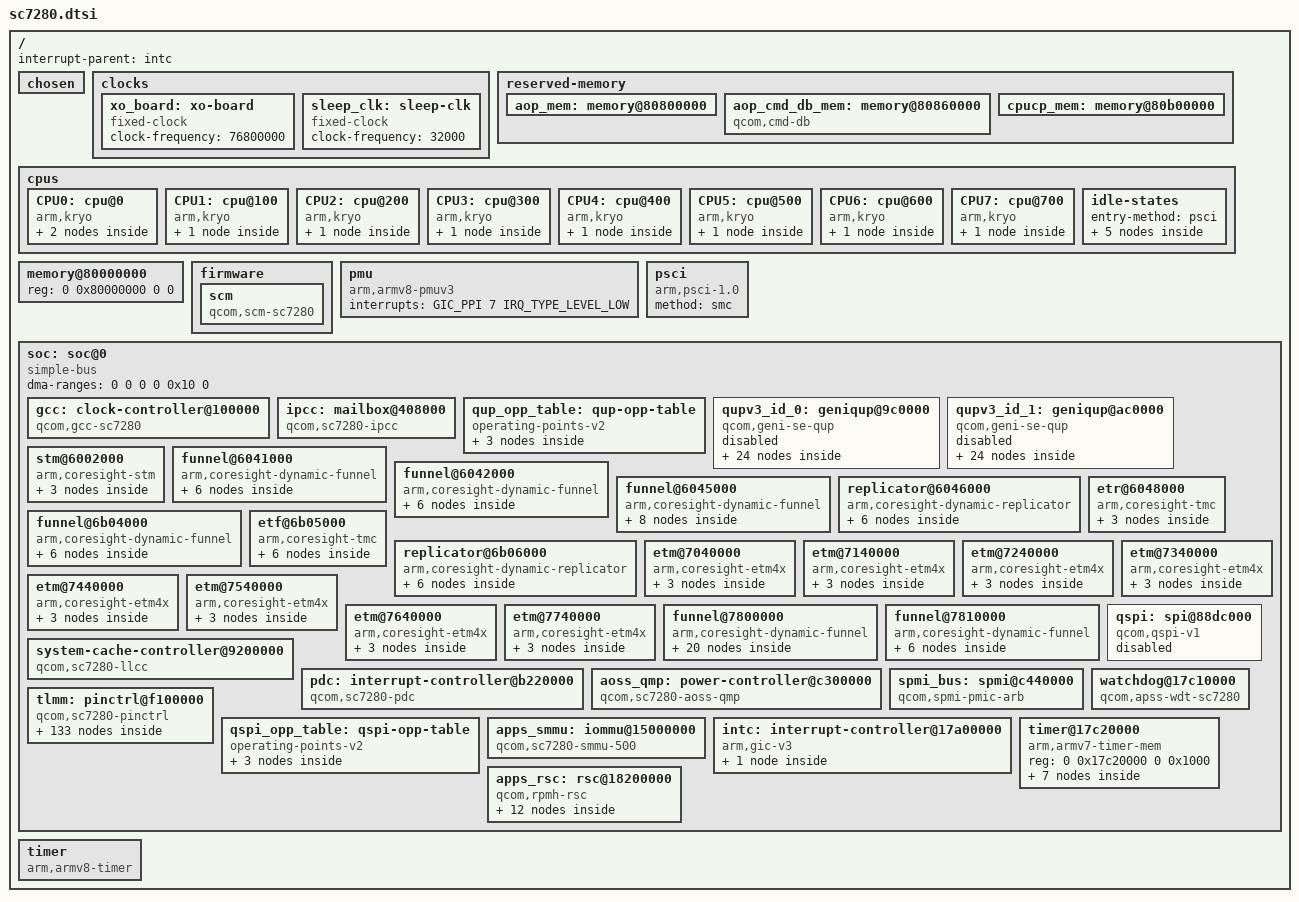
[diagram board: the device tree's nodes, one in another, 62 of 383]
// SPDX-License-Identifier: BSD-3-Clause
/*
 * sc7280 SoC device tree source
 *
 * Copyright (c) 2020-2021, The Linux Foundation. All rights reserved.
 */

#include <dt-bindings/clock/qcom,gcc-sc7280.h>
#include <dt-bindings/clock/qcom,rpmh.h>
#include <dt-bindings/interrupt-controller/arm-gic.h>
#include <dt-bindings/mailbox/qcom-ipcc.h>
#include <dt-bindings/power/qcom-aoss-qmp.h>
#include <dt-bindings/power/qcom-rpmpd.h>
#include <dt-bindings/soc/qcom,rpmh-rsc.h>

/ {
	interrupt-parent = <&intc>;

	#address-cells = <2>;
	#size-cells = <2>;

	chosen { };

	clocks {
		xo_board: xo-board {
			compatible = "fixed-clock";
			clock-frequency = <76800000>;
			#clock-cells = <0>;
		};

		sleep_clk: sleep-clk {
			compatible = "fixed-clock";
			clock-frequency = <32000>;
			#clock-cells = <0>;
		};
	};

	reserved-memory {
		#address-cells = <2>;
		#size-cells = <2>;
		ranges;

		aop_mem: memory@80800000 {
			reg = <0x0 0x80800000 0x0 0x60000>;
			no-map;
		};

		aop_cmd_db_mem: memory@80860000 {
			reg = <0x0 0x80860000 0x0 0x20000>;
			compatible = "qcom,cmd-db";
			no-map;
		};

		cpucp_mem: memory@80b00000 {
			no-map;
			reg = <0x0 0x80b00000 0x0 0x100000>;
		};
	};

	cpus {
		#address-cells = <2>;
		#size-cells = <0>;

		CPU0: cpu@0 {
			device_type = "cpu";
			compatible = "arm,kryo";
			reg = <0x0 0x0>;
			enable-method = "psci";
			cpu-idle-states = <&LITTLE_CPU_SLEEP_0
					   &LITTLE_CPU_SLEEP_1
					   &CLUSTER_SLEEP_0>;
			next-level-cache = <&L2_0>;
			L2_0: l2-cache {
				compatible = "cache";
				next-level-cache = <&L3_0>;
				L3_0: l3-cache {
					compatible = "cache";
				};
			};
		};

		CPU1: cpu@100 {
			device_type = "cpu";
			compatible = "arm,kryo";
			reg = <0x0 0x100>;
			enable-method = "psci";
			cpu-idle-states = <&LITTLE_CPU_SLEEP_0
					   &LITTLE_CPU_SLEEP_1
					   &CLUSTER_SLEEP_0>;
			next-level-cache = <&L2_100>;
			L2_100: l2-cache {
				compatible = "cache";
				next-level-cache = <&L3_0>;
			};
		};

		CPU2: cpu@200 {
			device_type = "cpu";
			compatible = "arm,kryo";
			reg = <0x0 0x200>;
			enable-method = "psci";
			cpu-idle-states = <&LITTLE_CPU_SLEEP_0
					   &LITTLE_CPU_SLEEP_1
					   &CLUSTER_SLEEP_0>;
			next-level-cache = <&L2_200>;
			L2_200: l2-cache {
				compatible = "cache";
				next-level-cache = <&L3_0>;
			};
		};

		CPU3: cpu@300 {
			device_type = "cpu";
			compatible = "arm,kryo";
			reg = <0x0 0x300>;
			enable-method = "psci";
			cpu-idle-states = <&LITTLE_CPU_SLEEP_0
					   &LITTLE_CPU_SLEEP_1
					   &CLUSTER_SLEEP_0>;
			next-level-cache = <&L2_300>;
			L2_300: l2-cache {
				compatible = "cache";
				next-level-cache = <&L3_0>;
			};
		};

		CPU4: cpu@400 {
			device_type = "cpu";
			compatible = "arm,kryo";
			reg = <0x0 0x400>;
			enable-method = "psci";
			cpu-idle-states = <&BIG_CPU_SLEEP_0
					   &BIG_CPU_SLEEP_1
					   &CLUSTER_SLEEP_0>;
			next-level-cache = <&L2_400>;
			L2_400: l2-cache {
				compatible = "cache";
				next-level-cache = <&L3_0>;
			};
		};

		CPU5: cpu@500 {
			device_type = "cpu";
			compatible = "arm,kryo";
			reg = <0x0 0x500>;
			enable-method = "psci";
			cpu-idle-states = <&BIG_CPU_SLEEP_0
					   &BIG_CPU_SLEEP_1
					   &CLUSTER_SLEEP_0>;
			next-level-cache = <&L2_500>;
			L2_500: l2-cache {
				compatible = "cache";
				next-level-cache = <&L3_0>;
			};
		};

		CPU6: cpu@600 {
			device_type = "cpu";
			compatible = "arm,kryo";
			reg = <0x0 0x600>;
			enable-method = "psci";
			cpu-idle-states = <&BIG_CPU_SLEEP_0
					   &BIG_CPU_SLEEP_1
					   &CLUSTER_SLEEP_0>;
			next-level-cache = <&L2_600>;
			L2_600: l2-cache {
				compatible = "cache";
				next-level-cache = <&L3_0>;
			};
		};

		CPU7: cpu@700 {
			device_type = "cpu";
			compatible = "arm,kryo";
			reg = <0x0 0x700>;
			enable-method = "psci";
			cpu-idle-states = <&BIG_CPU_SLEEP_0
					   &BIG_CPU_SLEEP_1
					   &CLUSTER_SLEEP_0>;
			next-level-cache = <&L2_700>;
			L2_700: l2-cache {
				compatible = "cache";
				next-level-cache = <&L3_0>;
			};
		};

		idle-states {
			entry-method = "psci";

			LITTLE_CPU_SLEEP_0: cpu-sleep-0-0 {
				compatible = "arm,idle-state";
				idle-state-name = "little-power-down";
				arm,psci-suspend-param = <0x40000003>;
				entry-latency-us = <549>;
				exit-latency-us = <901>;
				min-residency-us = <1774>;
				local-timer-stop;
			};

			LITTLE_CPU_SLEEP_1: cpu-sleep-0-1 {
				compatible = "arm,idle-state";
				idle-state-name = "little-rail-power-down";
				arm,psci-suspend-param = <0x40000004>;
				entry-latency-us = <702>;
				exit-latency-us = <915>;
				min-residency-us = <4001>;
				local-timer-stop;
			};

			BIG_CPU_SLEEP_0: cpu-sleep-1-0 {
				compatible = "arm,idle-state";
				idle-state-name = "big-power-down";
				arm,psci-suspend-param = <0x40000003>;
				entry-latency-us = <523>;
				exit-latency-us = <1244>;
				min-residency-us = <2207>;
				local-timer-stop;
			};

			BIG_CPU_SLEEP_1: cpu-sleep-1-1 {
				compatible = "arm,idle-state";
				idle-state-name = "big-rail-power-down";
				arm,psci-suspend-param = <0x40000004>;
				entry-latency-us = <526>;
				exit-latency-us = <1854>;
				min-residency-us = <5555>;
				local-timer-stop;
			};

			CLUSTER_SLEEP_0: cluster-sleep-0 {
				compatible = "arm,idle-state";
				idle-state-name = "cluster-power-down";
				arm,psci-suspend-param = <0x40003444>;
				entry-latency-us = <3263>;
				exit-latency-us = <6562>;
				min-residency-us = <9926>;
				local-timer-stop;
			};
		};
	};

	memory@80000000 {
		device_type = "memory";
		/* We expect the bootloader to fill in the size */
		reg = <0 0x80000000 0 0>;
	};

	firmware {
		scm {
			compatible = "qcom,scm-sc7280", "qcom,scm";
		};
	};

	pmu {
		compatible = "arm,armv8-pmuv3";
		interrupts = <GIC_PPI 7 IRQ_TYPE_LEVEL_LOW>;
	};

	psci {
		compatible = "arm,psci-1.0";
		method = "smc";
	};

	soc: soc@0 {
		#address-cells = <2>;
		#size-cells = <2>;
		ranges = <0 0 0 0 0x10 0>;
		dma-ranges = <0 0 0 0 0x10 0>;
		compatible = "simple-bus";

		gcc: clock-controller@100000 {
			compatible = "qcom,gcc-sc7280";
			reg = <0 0x00100000 0 0x1f0000>;
			clocks = <&rpmhcc RPMH_CXO_CLK>,
				 <&rpmhcc RPMH_CXO_CLK_A>, <&sleep_clk>,
				 <0>, <0>, <0>, <0>, <0>, <0>;
			clock-names = "bi_tcxo", "bi_tcxo_ao", "sleep_clk",
				      "pcie_0_pipe_clk", "pcie_1_pipe-clk",
				      "ufs_phy_rx_symbol_0_clk", "ufs_phy_rx_symbol_1_clk",
				      "ufs_phy_tx_symbol_0_clk",
				      "usb3_phy_wrapper_gcc_usb30_pipe_clk";
			#clock-cells = <1>;
			#reset-cells = <1>;
			#power-domain-cells = <1>;
		};

		ipcc: mailbox@408000 {
			compatible = "qcom,sc7280-ipcc", "qcom,ipcc";
			reg = <0 0x00408000 0 0x1000>;
			interrupts = <GIC_SPI 229 IRQ_TYPE_LEVEL_HIGH>;
			interrupt-controller;
			#interrupt-cells = <3>;
			#mbox-cells = <2>;
		};

		qup_opp_table: qup-opp-table {
			compatible = "operating-points-v2";

			opp-75000000 {
				opp-hz = /bits/ 64 <75000000>;
				required-opps = <&rpmhpd_opp_low_svs>;
			};

			opp-100000000 {
				opp-hz = /bits/ 64 <100000000>;
				required-opps = <&rpmhpd_opp_svs>;
			};

			opp-128000000 {
				opp-hz = /bits/ 64 <128000000>;
				required-opps = <&rpmhpd_opp_nom>;
			};
		};

		qupv3_id_0: geniqup@9c0000 {
			compatible = "qcom,geni-se-qup";
			reg = <0 0x009c0000 0 0x2000>;
			clock-names = "m-ahb", "s-ahb";
			clocks = <&gcc GCC_QUPV3_WRAP_0_M_AHB_CLK>,
				 <&gcc GCC_QUPV3_WRAP_0_S_AHB_CLK>;
			#address-cells = <2>;
			#size-cells = <2>;
			ranges;
			iommus = <&apps_smmu 0x123 0x0>;
			interconnects = <&clk_virt MASTER_QUP_CORE_0 0 &clk_virt SLAVE_QUP_CORE_0 0>;
			interconnect-names = "qup-core";
			status = "disabled";

			i2c0: i2c@980000 {
				compatible = "qcom,geni-i2c";
				reg = <0 0x00980000 0 0x4000>;
				clock-names = "se";
				clocks = <&gcc GCC_QUPV3_WRAP0_S0_CLK>;
				pinctrl-names = "default";
				pinctrl-0 = <&qup_i2c0_data_clk>;
				interrupts = <GIC_SPI 601 IRQ_TYPE_LEVEL_HIGH>;
				#address-cells = <1>;
				#size-cells = <0>;
				interconnects = <&clk_virt MASTER_QUP_CORE_0 0 &clk_virt SLAVE_QUP_CORE_0 0>,
						<&gem_noc MASTER_APPSS_PROC 0 &cnoc2 SLAVE_QUP_0 0>,
						<&aggre1_noc MASTER_QUP_0 0 &mc_virt SLAVE_EBI1 0>;
				interconnect-names = "qup-core", "qup-config",
							"qup-memory";
				status = "disabled";
			};

			spi0: spi@980000 {
				compatible = "qcom,geni-spi";
				reg = <0 0x00980000 0 0x4000>;
				clock-names = "se";
				clocks = <&gcc GCC_QUPV3_WRAP0_S0_CLK>;
				pinctrl-names = "default";
				pinctrl-0 = <&qup_spi0_data_clk>, <&qup_spi0_cs>, <&qup_spi0_cs_gpio>;
				interrupts = <GIC_SPI 601 IRQ_TYPE_LEVEL_HIGH>;
				#address-cells = <1>;
				#size-cells = <0>;
				power-domains = <&rpmhpd SC7280_CX>;
				operating-points-v2 = <&qup_opp_table>;
				interconnects = <&clk_virt MASTER_QUP_CORE_0 0 &clk_virt SLAVE_QUP_CORE_0 0>,
						<&gem_noc MASTER_APPSS_PROC 0 &cnoc2 SLAVE_QUP_0 0>;
				interconnect-names = "qup-core", "qup-config";
				status = "disabled";
			};

			uart0: serial@980000 {
				compatible = "qcom,geni-uart";
				reg = <0 0x00980000 0 0x4000>;
				clock-names = "se";
				clocks = <&gcc GCC_QUPV3_WRAP0_S0_CLK>;
				pinctrl-names = "default";
				pinctrl-0 = <&qup_uart0_cts>, <&qup_uart0_rts>, <&qup_uart0_tx>, <&qup_uart0_rx>;
				interrupts = <GIC_SPI 601 IRQ_TYPE_LEVEL_HIGH>;
				power-domains = <&rpmhpd SC7280_CX>;
				operating-points-v2 = <&qup_opp_table>;
				interconnects = <&clk_virt MASTER_QUP_CORE_0 0 &clk_virt SLAVE_QUP_CORE_0 0>,
						<&gem_noc MASTER_APPSS_PROC 0 &cnoc2 SLAVE_QUP_0 0>;
				interconnect-names = "qup-core", "qup-config";
				status = "disabled";
			};

			i2c1: i2c@984000 {
				compatible = "qcom,geni-i2c";
				reg = <0 0x00984000 0 0x4000>;
				clock-names = "se";
				clocks = <&gcc GCC_QUPV3_WRAP0_S1_CLK>;
				pinctrl-names = "default";
				pinctrl-0 = <&qup_i2c1_data_clk>;
				interrupts = <GIC_SPI 602 IRQ_TYPE_LEVEL_HIGH>;
				#address-cells = <1>;
				#size-cells = <0>;
				interconnects = <&clk_virt MASTER_QUP_CORE_0 0 &clk_virt SLAVE_QUP_CORE_0 0>,
						<&gem_noc MASTER_APPSS_PROC 0 &cnoc2 SLAVE_QUP_0 0>,
						<&aggre1_noc MASTER_QUP_0 0 &mc_virt SLAVE_EBI1 0>;
				interconnect-names = "qup-core", "qup-config",
							"qup-memory";
				status = "disabled";
			};

			spi1: spi@984000 {
				compatible = "qcom,geni-spi";
				reg = <0 0x00984000 0 0x4000>;
				clock-names = "se";
				clocks = <&gcc GCC_QUPV3_WRAP0_S1_CLK>;
				pinctrl-names = "default";
				pinctrl-0 = <&qup_spi1_data_clk>, <&qup_spi1_cs>, <&qup_spi1_cs_gpio>;
				interrupts = <GIC_SPI 602 IRQ_TYPE_LEVEL_HIGH>;
				#address-cells = <1>;
				#size-cells = <0>;
				power-domains = <&rpmhpd SC7280_CX>;
				operating-points-v2 = <&qup_opp_table>;
				interconnects = <&clk_virt MASTER_QUP_CORE_0 0 &clk_virt SLAVE_QUP_CORE_0 0>,
						<&gem_noc MASTER_APPSS_PROC 0 &cnoc2 SLAVE_QUP_0 0>;
				interconnect-names = "qup-core", "qup-config";
				status = "disabled";
			};

			uart1: serial@984000 {
				compatible = "qcom,geni-uart";
				reg = <0 0x00984000 0 0x4000>;
				clock-names = "se";
				clocks = <&gcc GCC_QUPV3_WRAP0_S1_CLK>;
				pinctrl-names = "default";
				pinctrl-0 = <&qup_uart1_cts>, <&qup_uart1_rts>, <&qup_uart1_tx>, <&qup_uart1_rx>;
				interrupts = <GIC_SPI 602 IRQ_TYPE_LEVEL_HIGH>;
				power-domains = <&rpmhpd SC7280_CX>;
				operating-points-v2 = <&qup_opp_table>;
				interconnects = <&clk_virt MASTER_QUP_CORE_0 0 &clk_virt SLAVE_QUP_CORE_0 0>,
						<&gem_noc MASTER_APPSS_PROC 0 &cnoc2 SLAVE_QUP_0 0>;
				interconnect-names = "qup-core", "qup-config";
				status = "disabled";
			};

			i2c2: i2c@988000 {
				compatible = "qcom,geni-i2c";
				reg = <0 0x00988000 0 0x4000>;
				clock-names = "se";
				clocks = <&gcc GCC_QUPV3_WRAP0_S2_CLK>;
				pinctrl-names = "default";
				pinctrl-0 = <&qup_i2c2_data_clk>;
				interrupts = <GIC_SPI 603 IRQ_TYPE_LEVEL_HIGH>;
				#address-cells = <1>;
				#size-cells = <0>;
				interconnects = <&clk_virt MASTER_QUP_CORE_0 0 &clk_virt SLAVE_QUP_CORE_0 0>,
						<&gem_noc MASTER_APPSS_PROC 0 &cnoc2 SLAVE_QUP_0 0>,
						<&aggre1_noc MASTER_QUP_0 0 &mc_virt SLAVE_EBI1 0>;
				interconnect-names = "qup-core", "qup-config",
							"qup-memory";
				status = "disabled";
			};

			spi2: spi@988000 {
				compatible = "qcom,geni-spi";
				reg = <0 0x00988000 0 0x4000>;
				clock-names = "se";
				clocks = <&gcc GCC_QUPV3_WRAP0_S2_CLK>;
				pinctrl-names = "default";
				pinctrl-0 = <&qup_spi2_data_clk>, <&qup_spi2_cs>, <&qup_spi2_cs_gpio>;
				interrupts = <GIC_SPI 603 IRQ_TYPE_LEVEL_HIGH>;
				#address-cells = <1>;
				#size-cells = <0>;
				power-domains = <&rpmhpd SC7280_CX>;
				operating-points-v2 = <&qup_opp_table>;
				interconnects = <&clk_virt MASTER_QUP_CORE_0 0 &clk_virt SLAVE_QUP_CORE_0 0>,
						<&gem_noc MASTER_APPSS_PROC 0 &cnoc2 SLAVE_QUP_0 0>;
				interconnect-names = "qup-core", "qup-config";
				status = "disabled";
			};

			uart2: serial@988000 {
				compatible = "qcom,geni-uart";
				reg = <0 0x00988000 0 0x4000>;
				clock-names = "se";
				clocks = <&gcc GCC_QUPV3_WRAP0_S2_CLK>;
				pinctrl-names = "default";
				pinctrl-0 = <&qup_uart2_cts>, <&qup_uart2_rts>, <&qup_uart2_tx>, <&qup_uart2_rx>;
				interrupts = <GIC_SPI 603 IRQ_TYPE_LEVEL_HIGH>;
				power-domains = <&rpmhpd SC7280_CX>;
				operating-points-v2 = <&qup_opp_table>;
				interconnects = <&clk_virt MASTER_QUP_CORE_0 0 &clk_virt SLAVE_QUP_CORE_0 0>,
						<&gem_noc MASTER_APPSS_PROC 0 &cnoc2 SLAVE_QUP_0 0>;
				interconnect-names = "qup-core", "qup-config";
				status = "disabled";
			};

			i2c3: i2c@98c000 {
				compatible = "qcom,geni-i2c";
				reg = <0 0x0098c000 0 0x4000>;
				clock-names = "se";
				clocks = <&gcc GCC_QUPV3_WRAP0_S3_CLK>;
				pinctrl-names = "default";
				pinctrl-0 = <&qup_i2c3_data_clk>;
				interrupts = <GIC_SPI 604 IRQ_TYPE_LEVEL_HIGH>;
				#address-cells = <1>;
				#size-cells = <0>;
				interconnects = <&clk_virt MASTER_QUP_CORE_0 0 &clk_virt SLAVE_QUP_CORE_0 0>,
						<&gem_noc MASTER_APPSS_PROC 0 &cnoc2 SLAVE_QUP_0 0>,
						<&aggre1_noc MASTER_QUP_0 0 &mc_virt SLAVE_EBI1 0>;
				interconnect-names = "qup-core", "qup-config",
							"qup-memory";
				status = "disabled";
			};

			spi3: spi@98c000 {
				compatible = "qcom,geni-spi";
				reg = <0 0x0098c000 0 0x4000>;
				clock-names = "se";
				clocks = <&gcc GCC_QUPV3_WRAP0_S3_CLK>;
				pinctrl-names = "default";
				pinctrl-0 = <&qup_spi3_data_clk>, <&qup_spi3_cs>, <&qup_spi3_cs_gpio>;
				interrupts = <GIC_SPI 604 IRQ_TYPE_LEVEL_HIGH>;
				#address-cells = <1>;
				#size-cells = <0>;
				power-domains = <&rpmhpd SC7280_CX>;
				operating-points-v2 = <&qup_opp_table>;
				interconnects = <&clk_virt MASTER_QUP_CORE_0 0 &clk_virt SLAVE_QUP_CORE_0 0>,
						<&gem_noc MASTER_APPSS_PROC 0 &cnoc2 SLAVE_QUP_0 0>;
				interconnect-names = "qup-core", "qup-config";
				status = "disabled";
			};

			uart3: serial@98c000 {
				compatible = "qcom,geni-uart";
				reg = <0 0x0098c000 0 0x4000>;
				clock-names = "se";
				clocks = <&gcc GCC_QUPV3_WRAP0_S3_CLK>;
				pinctrl-names = "default";
				pinctrl-0 = <&qup_uart3_cts>, <&qup_uart3_rts>, <&qup_uart3_tx>, <&qup_uart3_rx>;
				interrupts = <GIC_SPI 604 IRQ_TYPE_LEVEL_HIGH>;
				power-domains = <&rpmhpd SC7280_CX>;
				operating-points-v2 = <&qup_opp_table>;
				interconnects = <&clk_virt MASTER_QUP_CORE_0 0 &clk_virt SLAVE_QUP_CORE_0 0>,
						<&gem_noc MASTER_APPSS_PROC 0 &cnoc2 SLAVE_QUP_0 0>;
				interconnect-names = "qup-core", "qup-config";
				status = "disabled";
			};

			i2c4: i2c@990000 {
				compatible = "qcom,geni-i2c";
				reg = <0 0x00990000 0 0x4000>;
				clock-names = "se";
				clocks = <&gcc GCC_QUPV3_WRAP0_S4_CLK>;
				pinctrl-names = "default";
				pinctrl-0 = <&qup_i2c4_data_clk>;
				interrupts = <GIC_SPI 605 IRQ_TYPE_LEVEL_HIGH>;
				#address-cells = <1>;
				#size-cells = <0>;
				interconnects = <&clk_virt MASTER_QUP_CORE_0 0 &clk_virt SLAVE_QUP_CORE_0 0>,
						<&gem_noc MASTER_APPSS_PROC 0 &cnoc2 SLAVE_QUP_0 0>,
						<&aggre1_noc MASTER_QUP_0 0 &mc_virt SLAVE_EBI1 0>;
				interconnect-names = "qup-core", "qup-config",
							"qup-memory";
				status = "disabled";
			};

			spi4: spi@990000 {
				compatible = "qcom,geni-spi";
				reg = <0 0x00990000 0 0x4000>;
				clock-names = "se";
				clocks = <&gcc GCC_QUPV3_WRAP0_S4_CLK>;
				pinctrl-names = "default";
				pinctrl-0 = <&qup_spi4_data_clk>, <&qup_spi4_cs>, <&qup_spi4_cs_gpio>;
				interrupts = <GIC_SPI 605 IRQ_TYPE_LEVEL_HIGH>;
				#address-cells = <1>;
				#size-cells = <0>;
				power-domains = <&rpmhpd SC7280_CX>;
				operating-points-v2 = <&qup_opp_table>;
				interconnects = <&clk_virt MASTER_QUP_CORE_0 0 &clk_virt SLAVE_QUP_CORE_0 0>,
						<&gem_noc MASTER_APPSS_PROC 0 &cnoc2 SLAVE_QUP_0 0>;
				interconnect-names = "qup-core", "qup-config";
				status = "disabled";
			};

			uart4: serial@990000 {
				compatible = "qcom,geni-uart";
				reg = <0 0x00990000 0 0x4000>;
				clock-names = "se";
				clocks = <&gcc GCC_QUPV3_WRAP0_S4_CLK>;
				pinctrl-names = "default";
				pinctrl-0 = <&qup_uart4_cts>, <&qup_uart4_rts>, <&qup_uart4_tx>, <&qup_uart4_rx>;
				interrupts = <GIC_SPI 605 IRQ_TYPE_LEVEL_HIGH>;
				power-domains = <&rpmhpd SC7280_CX>;
				operating-points-v2 = <&qup_opp_table>;
				interconnects = <&clk_virt MASTER_QUP_CORE_0 0 &clk_virt SLAVE_QUP_CORE_0 0>,
						<&gem_noc MASTER_APPSS_PROC 0 &cnoc2 SLAVE_QUP_0 0>;
				interconnect-names = "qup-core", "qup-config";
				status = "disabled";
			};

			i2c5: i2c@994000 {
				compatible = "qcom,geni-i2c";
				reg = <0 0x00994000 0 0x4000>;
				clock-names = "se";
				clocks = <&gcc GCC_QUPV3_WRAP0_S5_CLK>;
				pinctrl-names = "default";
				pinctrl-0 = <&qup_i2c5_data_clk>;
				interrupts = <GIC_SPI 606 IRQ_TYPE_LEVEL_HIGH>;
				#address-cells = <1>;
				#size-cells = <0>;
				interconnects = <&clk_virt MASTER_QUP_CORE_0 0 &clk_virt SLAVE_QUP_CORE_0 0>,
						<&gem_noc MASTER_APPSS_PROC 0 &cnoc2 SLAVE_QUP_0 0>,
						<&aggre1_noc MASTER_QUP_0 0 &mc_virt SLAVE_EBI1 0>;
				interconnect-names = "qup-core", "qup-config",
							"qup-memory";
				status = "disabled";
			};

			spi5: spi@994000 {
				compatible = "qcom,geni-spi";
				reg = <0 0x00994000 0 0x4000>;
				clock-names = "se";
				clocks = <&gcc GCC_QUPV3_WRAP0_S5_CLK>;
				pinctrl-names = "default";
				pinctrl-0 = <&qup_spi5_data_clk>, <&qup_spi5_cs>, <&qup_spi5_cs_gpio>;
				interrupts = <GIC_SPI 606 IRQ_TYPE_LEVEL_HIGH>;
				#address-cells = <1>;
				#size-cells = <0>;
				power-domains = <&rpmhpd SC7280_CX>;
				operating-points-v2 = <&qup_opp_table>;
				interconnects = <&clk_virt MASTER_QUP_CORE_0 0 &clk_virt SLAVE_QUP_CORE_0 0>,
						<&gem_noc MASTER_APPSS_PROC 0 &cnoc2 SLAVE_QUP_0 0>;
				interconnect-names = "qup-core", "qup-config";
				status = "disabled";
			};

			uart5: serial@994000 {
				compatible = "qcom,geni-debug-uart";
				reg = <0 0x00994000 0 0x4000>;
				clock-names = "se";
				clocks = <&gcc GCC_QUPV3_WRAP0_S5_CLK>;
				pinctrl-names = "default";
				pinctrl-0 = <&qup_uart5_cts>, <&qup_uart5_rts>, <&qup_uart5_tx>, <&qup_uart5_rx>;
				interrupts = <GIC_SPI 606 IRQ_TYPE_LEVEL_HIGH>;
				power-domains = <&rpmhpd SC7280_CX>;
				operating-points-v2 = <&qup_opp_table>;
				interconnects = <&clk_virt MASTER_QUP_CORE_0 0 &clk_virt SLAVE_QUP_CORE_0 0>,
						<&gem_noc MASTER_APPSS_PROC 0 &cnoc2 SLAVE_QUP_0 0>;
				interconnect-names = "qup-core", "qup-config";
				status = "disabled";
			};

			i2c6: i2c@998000 {
				compatible = "qcom,geni-i2c";
				reg = <0 0x00998000 0 0x4000>;
				clock-names = "se";
				clocks = <&gcc GCC_QUPV3_WRAP0_S6_CLK>;
				pinctrl-names = "default";
				pinctrl-0 = <&qup_i2c6_data_clk>;
				interrupts = <GIC_SPI 607 IRQ_TYPE_LEVEL_HIGH>;
				#address-cells = <1>;
				#size-cells = <0>;
				interconnects = <&clk_virt MASTER_QUP_CORE_0 0 &clk_virt SLAVE_QUP_CORE_0 0>,
						<&gem_noc MASTER_APPSS_PROC 0 &cnoc2 SLAVE_QUP_0 0>,
						<&aggre1_noc MASTER_QUP_0 0 &mc_virt SLAVE_EBI1 0>;
				interconnect-names = "qup-core", "qup-config",
							"qup-memory";
				status = "disabled";
			};

			spi6: spi@998000 {
				compatible = "qcom,geni-spi";
				reg = <0 0x00998000 0 0x4000>;
				clock-names = "se";
				clocks = <&gcc GCC_QUPV3_WRAP0_S6_CLK>;
				pinctrl-names = "default";
				pinctrl-0 = <&qup_spi6_data_clk>, <&qup_spi6_cs>, <&qup_spi6_cs_gpio>;
				interrupts = <GIC_SPI 607 IRQ_TYPE_LEVEL_HIGH>;
				#address-cells = <1>;
				#size-cells = <0>;
				power-domains = <&rpmhpd SC7280_CX>;
				operating-points-v2 = <&qup_opp_table>;
				interconnects = <&clk_virt MASTER_QUP_CORE_0 0 &clk_virt SLAVE_QUP_CORE_0 0>,
						<&gem_noc MASTER_APPSS_PROC 0 &cnoc2 SLAVE_QUP_0 0>;
				interconnect-names = "qup-core", "qup-config";
				status = "disabled";
			};

			uart6: serial@998000 {
				compatible = "qcom,geni-uart";
				reg = <0 0x00998000 0 0x4000>;
				clock-names = "se";
				clocks = <&gcc GCC_QUPV3_WRAP0_S6_CLK>;
				pinctrl-names = "default";
				pinctrl-0 = <&qup_uart6_cts>, <&qup_uart6_rts>, <&qup_uart6_tx>, <&qup_uart6_rx>;
				interrupts = <GIC_SPI 607 IRQ_TYPE_LEVEL_HIGH>;
				power-domains = <&rpmhpd SC7280_CX>;
				operating-points-v2 = <&qup_opp_table>;
				interconnects = <&clk_virt MASTER_QUP_CORE_0 0 &clk_virt SLAVE_QUP_CORE_0 0>,
						<&gem_noc MASTER_APPSS_PROC 0 &cnoc2 SLAVE_QUP_0 0>;
				interconnect-names = "qup-core", "qup-config";
				status = "disabled";
			};

			i2c7: i2c@99c000 {
				compatible = "qcom,geni-i2c";
				reg = <0 0x0099c000 0 0x4000>;
				clock-names = "se";
				clocks = <&gcc GCC_QUPV3_WRAP0_S7_CLK>;
				pinctrl-names = "default";
				pinctrl-0 = <&qup_i2c7_data_clk>;
				interrupts = <GIC_SPI 608 IRQ_TYPE_LEVEL_HIGH>;
				#address-cells = <1>;
				#size-cells = <0>;
				interconnects = <&clk_virt MASTER_QUP_CORE_0 0 &clk_virt SLAVE_QUP_CORE_0 0>,
						<&gem_noc MASTER_APPSS_PROC 0 &cnoc2 SLAVE_QUP_0 0>,
						<&aggre1_noc MASTER_QUP_0 0 &mc_virt SLAVE_EBI1 0>;
				interconnect-names = "qup-core", "qup-config",
							"qup-memory";
				status = "disabled";
			};

			spi7: spi@99c000 {
				compatible = "qcom,geni-spi";
				reg = <0 0x0099c000 0 0x4000>;
				clock-names = "se";
				clocks = <&gcc GCC_QUPV3_WRAP0_S7_CLK>;
				pinctrl-names = "default";
				pinctrl-0 = <&qup_spi7_data_clk>, <&qup_spi7_cs>, <&qup_spi7_cs_gpio>;
				interrupts = <GIC_SPI 608 IRQ_TYPE_LEVEL_HIGH>;
				#address-cells = <1>;
				#size-cells = <0>;
				power-domains = <&rpmhpd SC7280_CX>;
				operating-points-v2 = <&qup_opp_table>;
				interconnects = <&clk_virt MASTER_QUP_CORE_0 0 &clk_virt SLAVE_QUP_CORE_0 0>,
						<&gem_noc MASTER_APPSS_PROC 0 &cnoc2 SLAVE_QUP_0 0>;
				interconnect-names = "qup-core", "qup-config";
				status = "disabled";
			};

			uart7: serial@99c000 {
				compatible = "qcom,geni-uart";
				reg = <0 0x0099c000 0 0x4000>;
				clock-names = "se";
				clocks = <&gcc GCC_QUPV3_WRAP0_S7_CLK>;
				pinctrl-names = "default";
				pinctrl-0 = <&qup_uart7_cts>, <&qup_uart7_rts>, <&qup_uart7_tx>, <&qup_uart7_rx>;
				interrupts = <GIC_SPI 608 IRQ_TYPE_LEVEL_HIGH>;
				power-domains = <&rpmhpd SC7280_CX>;
				operating-points-v2 = <&qup_opp_table>;
				interconnects = <&clk_virt MASTER_QUP_CORE_0 0 &clk_virt SLAVE_QUP_CORE_0 0>,
						<&gem_noc MASTER_APPSS_PROC 0 &cnoc2 SLAVE_QUP_0 0>;
				interconnect-names = "qup-core", "qup-config";
				status = "disabled";
			};
		};

		qupv3_id_1: geniqup@ac0000 {
			compatible = "qcom,geni-se-qup";
			reg = <0 0x00ac0000 0 0x2000>;
			clock-names = "m-ahb", "s-ahb";
			clocks = <&gcc GCC_QUPV3_WRAP_1_M_AHB_CLK>,
				 <&gcc GCC_QUPV3_WRAP_1_S_AHB_CLK>;
			#address-cells = <2>;
			#size-cells = <2>;
			ranges;
			iommus = <&apps_smmu 0x43 0x0>;
			interconnects = <&clk_virt MASTER_QUP_CORE_1 0 &clk_virt SLAVE_QUP_CORE_1 0>;
			interconnect-names = "qup-core";
			status = "disabled";

			i2c8: i2c@a80000 {
				compatible = "qcom,geni-i2c";
				reg = <0 0x00a80000 0 0x4000>;
				clock-names = "se";
				clocks = <&gcc GCC_QUPV3_WRAP1_S0_CLK>;
				pinctrl-names = "default";
				pinctrl-0 = <&qup_i2c8_data_clk>;
				interrupts = <GIC_SPI 353 IRQ_TYPE_LEVEL_HIGH>;
				#address-cells = <1>;
				#size-cells = <0>;
				interconnects = <&clk_virt MASTER_QUP_CORE_1 0 &clk_virt SLAVE_QUP_CORE_1 0>,
						<&gem_noc MASTER_APPSS_PROC 0 &cnoc2 SLAVE_QUP_1 0>,
						<&aggre2_noc MASTER_QUP_1 0 &mc_virt SLAVE_EBI1 0>;
				interconnect-names = "qup-core", "qup-config",
							"qup-memory";
				status = "disabled";
			};

			spi8: spi@a80000 {
				compatible = "qcom,geni-spi";
				reg = <0 0x00a80000 0 0x4000>;
				clock-names = "se";
				clocks = <&gcc GCC_QUPV3_WRAP1_S0_CLK>;
				pinctrl-names = "default";
				pinctrl-0 = <&qup_spi8_data_clk>, <&qup_spi8_cs>, <&qup_spi8_cs_gpio>;
				interrupts = <GIC_SPI 353 IRQ_TYPE_LEVEL_HIGH>;
				#address-cells = <1>;
				#size-cells = <0>;
				power-domains = <&rpmhpd SC7280_CX>;
				operating-points-v2 = <&qup_opp_table>;
				interconnects = <&clk_virt MASTER_QUP_CORE_1 0 &clk_virt SLAVE_QUP_CORE_1 0>,
						<&gem_noc MASTER_APPSS_PROC 0 &cnoc2 SLAVE_QUP_1 0>;
				interconnect-names = "qup-core", "qup-config";
				status = "disabled";
			};

			uart8: serial@a80000 {
				compatible = "qcom,geni-uart";
				reg = <0 0x00a80000 0 0x4000>;
				clock-names = "se";
				clocks = <&gcc GCC_QUPV3_WRAP1_S0_CLK>;
				pinctrl-names = "default";
				pinctrl-0 = <&qup_uart8_cts>, <&qup_uart8_rts>, <&qup_uart8_tx>, <&qup_uart8_rx>;
				interrupts = <GIC_SPI 353 IRQ_TYPE_LEVEL_HIGH>;
				power-domains = <&rpmhpd SC7280_CX>;
				operating-points-v2 = <&qup_opp_table>;
				interconnects = <&clk_virt MASTER_QUP_CORE_1 0 &clk_virt SLAVE_QUP_CORE_1 0>,
						<&gem_noc MASTER_APPSS_PROC 0 &cnoc2 SLAVE_QUP_1 0>;
				interconnect-names = "qup-core", "qup-config";
				status = "disabled";
			};

			i2c9: i2c@a84000 {
				compatible = "qcom,geni-i2c";
				reg = <0 0x00a84000 0 0x4000>;
				clock-names = "se";
				clocks = <&gcc GCC_QUPV3_WRAP1_S1_CLK>;
				pinctrl-names = "default";
				pinctrl-0 = <&qup_i2c9_data_clk>;
				interrupts = <GIC_SPI 354 IRQ_TYPE_LEVEL_HIGH>;
				#address-cells = <1>;
				#size-cells = <0>;
				interconnects = <&clk_virt MASTER_QUP_CORE_1 0 &clk_virt SLAVE_QUP_CORE_1 0>,
						<&gem_noc MASTER_APPSS_PROC 0 &cnoc2 SLAVE_QUP_1 0>,
						<&aggre2_noc MASTER_QUP_1 0 &mc_virt SLAVE_EBI1 0>;
				interconnect-names = "qup-core", "qup-config",
							"qup-memory";
				status = "disabled";
			};

			spi9: spi@a84000 {
				compatible = "qcom,geni-spi";
				reg = <0 0x00a84000 0 0x4000>;
				clock-names = "se";
				clocks = <&gcc GCC_QUPV3_WRAP1_S1_CLK>;
				pinctrl-names = "default";
				pinctrl-0 = <&qup_spi9_data_clk>, <&qup_spi9_cs>, <&qup_spi9_cs_gpio>;
				interrupts = <GIC_SPI 354 IRQ_TYPE_LEVEL_HIGH>;
				#address-cells = <1>;
				#size-cells = <0>;
				power-domains = <&rpmhpd SC7280_CX>;
				operating-points-v2 = <&qup_opp_table>;
				interconnects = <&clk_virt MASTER_QUP_CORE_1 0 &clk_virt SLAVE_QUP_CORE_1 0>,
						<&gem_noc MASTER_APPSS_PROC 0 &cnoc2 SLAVE_QUP_1 0>;
				interconnect-names = "qup-core", "qup-config";
				status = "disabled";
			};

			uart9: serial@a84000 {
				compatible = "qcom,geni-uart";
				reg = <0 0x00a84000 0 0x4000>;
				clock-names = "se";
				clocks = <&gcc GCC_QUPV3_WRAP1_S1_CLK>;
				pinctrl-names = "default";
				pinctrl-0 = <&qup_uart9_cts>, <&qup_uart9_rts>, <&qup_uart9_tx>, <&qup_uart9_rx>;
				interrupts = <GIC_SPI 354 IRQ_TYPE_LEVEL_HIGH>;
				power-domains = <&rpmhpd SC7280_CX>;
				operating-points-v2 = <&qup_opp_table>;
				interconnects = <&clk_virt MASTER_QUP_CORE_1 0 &clk_virt SLAVE_QUP_CORE_1 0>,
						<&gem_noc MASTER_APPSS_PROC 0 &cnoc2 SLAVE_QUP_1 0>;
				interconnect-names = "qup-core", "qup-config";
				status = "disabled";
			};

			i2c10: i2c@a88000 {
				compatible = "qcom,geni-i2c";
				reg = <0 0x00a88000 0 0x4000>;
				clock-names = "se";
				clocks = <&gcc GCC_QUPV3_WRAP1_S2_CLK>;
				pinctrl-names = "default";
				pinctrl-0 = <&qup_i2c10_data_clk>;
				interrupts = <GIC_SPI 355 IRQ_TYPE_LEVEL_HIGH>;
				#address-cells = <1>;
				#size-cells = <0>;
				interconnects = <&clk_virt MASTER_QUP_CORE_1 0 &clk_virt SLAVE_QUP_CORE_1 0>,
						<&gem_noc MASTER_APPSS_PROC 0 &cnoc2 SLAVE_QUP_1 0>,
						<&aggre2_noc MASTER_QUP_1 0 &mc_virt SLAVE_EBI1 0>;
				interconnect-names = "qup-core", "qup-config",
							"qup-memory";
				status = "disabled";
			};

			spi10: spi@a88000 {
				compatible = "qcom,geni-spi";
				reg = <0 0x00a88000 0 0x4000>;
				clock-names = "se";
				clocks = <&gcc GCC_QUPV3_WRAP1_S2_CLK>;
				pinctrl-names = "default";
				pinctrl-0 = <&qup_spi10_data_clk>, <&qup_spi10_cs>, <&qup_spi10_cs_gpio>;
				interrupts = <GIC_SPI 355 IRQ_TYPE_LEVEL_HIGH>;
				#address-cells = <1>;
				#size-cells = <0>;
				power-domains = <&rpmhpd SC7280_CX>;
				operating-points-v2 = <&qup_opp_table>;
				interconnects = <&clk_virt MASTER_QUP_CORE_1 0 &clk_virt SLAVE_QUP_CORE_1 0>,
						<&gem_noc MASTER_APPSS_PROC 0 &cnoc2 SLAVE_QUP_1 0>;
				interconnect-names = "qup-core", "qup-config";
				status = "disabled";
			};

			uart10: serial@a88000 {
				compatible = "qcom,geni-uart";
				reg = <0 0x00a88000 0 0x4000>;
				clock-names = "se";
				clocks = <&gcc GCC_QUPV3_WRAP1_S2_CLK>;
				pinctrl-names = "default";
				pinctrl-0 = <&qup_uart10_cts>, <&qup_uart10_rts>, <&qup_uart10_tx>, <&qup_uart10_rx>;
				interrupts = <GIC_SPI 355 IRQ_TYPE_LEVEL_HIGH>;
				power-domains = <&rpmhpd SC7280_CX>;
				operating-points-v2 = <&qup_opp_table>;
				interconnects = <&clk_virt MASTER_QUP_CORE_1 0 &clk_virt SLAVE_QUP_CORE_1 0>,
						<&gem_noc MASTER_APPSS_PROC 0 &cnoc2 SLAVE_QUP_1 0>;
				interconnect-names = "qup-core", "qup-config";
				status = "disabled";
			};

			i2c11: i2c@a8c000 {
				compatible = "qcom,geni-i2c";
				reg = <0 0x00a8c000 0 0x4000>;
				clock-names = "se";
				clocks = <&gcc GCC_QUPV3_WRAP1_S3_CLK>;
				pinctrl-names = "default";
				pinctrl-0 = <&qup_i2c11_data_clk>;
				interrupts = <GIC_SPI 356 IRQ_TYPE_LEVEL_HIGH>;
				#address-cells = <1>;
				#size-cells = <0>;
				interconnects = <&clk_virt MASTER_QUP_CORE_1 0 &clk_virt SLAVE_QUP_CORE_1 0>,
						<&gem_noc MASTER_APPSS_PROC 0 &cnoc2 SLAVE_QUP_1 0>,
						<&aggre2_noc MASTER_QUP_1 0 &mc_virt SLAVE_EBI1 0>;
				interconnect-names = "qup-core", "qup-config",
							"qup-memory";
				status = "disabled";
			};

			spi11: spi@a8c000 {
				compatible = "qcom,geni-spi";
				reg = <0 0x00a8c000 0 0x4000>;
				clock-names = "se";
				clocks = <&gcc GCC_QUPV3_WRAP1_S3_CLK>;
				pinctrl-names = "default";
				pinctrl-0 = <&qup_spi11_data_clk>, <&qup_spi11_cs>, <&qup_spi11_cs_gpio>;
				interrupts = <GIC_SPI 356 IRQ_TYPE_LEVEL_HIGH>;
				#address-cells = <1>;
				#size-cells = <0>;
				power-domains = <&rpmhpd SC7280_CX>;
				operating-points-v2 = <&qup_opp_table>;
				interconnects = <&clk_virt MASTER_QUP_CORE_1 0 &clk_virt SLAVE_QUP_CORE_1 0>,
						<&gem_noc MASTER_APPSS_PROC 0 &cnoc2 SLAVE_QUP_1 0>;
				interconnect-names = "qup-core", "qup-config";
				status = "disabled";
			};

			uart11: serial@a8c000 {
				compatible = "qcom,geni-uart";
				reg = <0 0x00a8c000 0 0x4000>;
				clock-names = "se";
				clocks = <&gcc GCC_QUPV3_WRAP1_S3_CLK>;
				pinctrl-names = "default";
				pinctrl-0 = <&qup_uart11_cts>, <&qup_uart11_rts>, <&qup_uart11_tx>, <&qup_uart11_rx>;
				interrupts = <GIC_SPI 356 IRQ_TYPE_LEVEL_HIGH>;
				power-domains = <&rpmhpd SC7280_CX>;
				operating-points-v2 = <&qup_opp_table>;
				interconnects = <&clk_virt MASTER_QUP_CORE_1 0 &clk_virt SLAVE_QUP_CORE_1 0>,
						<&gem_noc MASTER_APPSS_PROC 0 &cnoc2 SLAVE_QUP_1 0>;
				interconnect-names = "qup-core", "qup-config";
				status = "disabled";
			};

			i2c12: i2c@a90000 {
				compatible = "qcom,geni-i2c";
				reg = <0 0x00a90000 0 0x4000>;
				clock-names = "se";
				clocks = <&gcc GCC_QUPV3_WRAP1_S4_CLK>;
				pinctrl-names = "default";
				pinctrl-0 = <&qup_i2c12_data_clk>;
				interrupts = <GIC_SPI 357 IRQ_TYPE_LEVEL_HIGH>;
				#address-cells = <1>;
				#size-cells = <0>;
				interconnects = <&clk_virt MASTER_QUP_CORE_1 0 &clk_virt SLAVE_QUP_CORE_1 0>,
						<&gem_noc MASTER_APPSS_PROC 0 &cnoc2 SLAVE_QUP_1 0>,
						<&aggre2_noc MASTER_QUP_1 0 &mc_virt SLAVE_EBI1 0>;
				interconnect-names = "qup-core", "qup-config",
							"qup-memory";
				status = "disabled";
			};

			spi12: spi@a90000 {
				compatible = "qcom,geni-spi";
				reg = <0 0x00a90000 0 0x4000>;
				clock-names = "se";
				clocks = <&gcc GCC_QUPV3_WRAP1_S4_CLK>;
				pinctrl-names = "default";
				pinctrl-0 = <&qup_spi12_data_clk>, <&qup_spi12_cs>, <&qup_spi12_cs_gpio>;
				interrupts = <GIC_SPI 357 IRQ_TYPE_LEVEL_HIGH>;
				#address-cells = <1>;
				#size-cells = <0>;
				power-domains = <&rpmhpd SC7280_CX>;
				operating-points-v2 = <&qup_opp_table>;
				interconnects = <&clk_virt MASTER_QUP_CORE_1 0 &clk_virt SLAVE_QUP_CORE_1 0>,
						<&gem_noc MASTER_APPSS_PROC 0 &cnoc2 SLAVE_QUP_1 0>;
				interconnect-names = "qup-core", "qup-config";
				status = "disabled";
			};

			uart12: serial@a90000 {
				compatible = "qcom,geni-uart";
				reg = <0 0x00a90000 0 0x4000>;
				clock-names = "se";
				clocks = <&gcc GCC_QUPV3_WRAP1_S4_CLK>;
				pinctrl-names = "default";
				pinctrl-0 = <&qup_uart12_cts>, <&qup_uart12_rts>, <&qup_uart12_tx>, <&qup_uart12_rx>;
				interrupts = <GIC_SPI 357 IRQ_TYPE_LEVEL_HIGH>;
				power-domains = <&rpmhpd SC7280_CX>;
				operating-points-v2 = <&qup_opp_table>;
				interconnects = <&clk_virt MASTER_QUP_CORE_1 0 &clk_virt SLAVE_QUP_CORE_1 0>,
						<&gem_noc MASTER_APPSS_PROC 0 &cnoc2 SLAVE_QUP_1 0>;
				interconnect-names = "qup-core", "qup-config";
				status = "disabled";
			};

			i2c13: i2c@a94000 {
				compatible = "qcom,geni-i2c";
				reg = <0 0x00a94000 0 0x4000>;
				clock-names = "se";
				clocks = <&gcc GCC_QUPV3_WRAP1_S5_CLK>;
				pinctrl-names = "default";
				pinctrl-0 = <&qup_i2c13_data_clk>;
				interrupts = <GIC_SPI 358 IRQ_TYPE_LEVEL_HIGH>;
				#address-cells = <1>;
				#size-cells = <0>;
				interconnects = <&clk_virt MASTER_QUP_CORE_1 0 &clk_virt SLAVE_QUP_CORE_1 0>,
						<&gem_noc MASTER_APPSS_PROC 0 &cnoc2 SLAVE_QUP_1 0>,
						<&aggre2_noc MASTER_QUP_1 0 &mc_virt SLAVE_EBI1 0>;
				interconnect-names = "qup-core", "qup-config",
							"qup-memory";
				status = "disabled";
			};

			spi13: spi@a94000 {
				compatible = "qcom,geni-spi";
				reg = <0 0x00a94000 0 0x4000>;
				clock-names = "se";
				clocks = <&gcc GCC_QUPV3_WRAP1_S5_CLK>;
				pinctrl-names = "default";
				pinctrl-0 = <&qup_spi13_data_clk>, <&qup_spi13_cs>, <&qup_spi13_cs_gpio>;
				interrupts = <GIC_SPI 358 IRQ_TYPE_LEVEL_HIGH>;
				#address-cells = <1>;
				#size-cells = <0>;
				power-domains = <&rpmhpd SC7280_CX>;
				operating-points-v2 = <&qup_opp_table>;
				interconnects = <&clk_virt MASTER_QUP_CORE_1 0 &clk_virt SLAVE_QUP_CORE_1 0>,
						<&gem_noc MASTER_APPSS_PROC 0 &cnoc2 SLAVE_QUP_1 0>;
				interconnect-names = "qup-core", "qup-config";
				status = "disabled";
			};

			uart13: serial@a94000 {
				compatible = "qcom,geni-uart";
				reg = <0 0x00a94000 0 0x4000>;
				clock-names = "se";
				clocks = <&gcc GCC_QUPV3_WRAP1_S5_CLK>;
				pinctrl-names = "default";
				pinctrl-0 = <&qup_uart13_cts>, <&qup_uart13_rts>, <&qup_uart13_tx>, <&qup_uart13_rx>;
				interrupts = <GIC_SPI 358 IRQ_TYPE_LEVEL_HIGH>;
				power-domains = <&rpmhpd SC7280_CX>;
				operating-points-v2 = <&qup_opp_table>;
				interconnects = <&clk_virt MASTER_QUP_CORE_1 0 &clk_virt SLAVE_QUP_CORE_1 0>,
						<&gem_noc MASTER_APPSS_PROC 0 &cnoc2 SLAVE_QUP_1 0>;
				interconnect-names = "qup-core", "qup-config";
				status = "disabled";
			};

			i2c14: i2c@a98000 {
				compatible = "qcom,geni-i2c";
				reg = <0 0x00a98000 0 0x4000>;
				clock-names = "se";
				clocks = <&gcc GCC_QUPV3_WRAP1_S6_CLK>;
				pinctrl-names = "default";
				pinctrl-0 = <&qup_i2c14_data_clk>;
				interrupts = <GIC_SPI 368 IRQ_TYPE_LEVEL_HIGH>;
				#address-cells = <1>;
				#size-cells = <0>;
				interconnects = <&clk_virt MASTER_QUP_CORE_1 0 &clk_virt SLAVE_QUP_CORE_1 0>,
						<&gem_noc MASTER_APPSS_PROC 0 &cnoc2 SLAVE_QUP_1 0>,
						<&aggre2_noc MASTER_QUP_1 0 &mc_virt SLAVE_EBI1 0>;
				interconnect-names = "qup-core", "qup-config",
							"qup-memory";
				status = "disabled";
			};

			spi14: spi@a98000 {
				compatible = "qcom,geni-spi";
				reg = <0 0x00a98000 0 0x4000>;
				clock-names = "se";
				clocks = <&gcc GCC_QUPV3_WRAP1_S6_CLK>;
				pinctrl-names = "default";
				pinctrl-0 = <&qup_spi14_data_clk>, <&qup_spi14_cs>, <&qup_spi14_cs_gpio>;
				interrupts = <GIC_SPI 368 IRQ_TYPE_LEVEL_HIGH>;
				#address-cells = <1>;
				#size-cells = <0>;
				power-domains = <&rpmhpd SC7280_CX>;
				operating-points-v2 = <&qup_opp_table>;
				interconnects = <&clk_virt MASTER_QUP_CORE_1 0 &clk_virt SLAVE_QUP_CORE_1 0>,
						<&gem_noc MASTER_APPSS_PROC 0 &cnoc2 SLAVE_QUP_1 0>;
				interconnect-names = "qup-core", "qup-config";
				status = "disabled";
			};

			uart14: serial@a98000 {
				compatible = "qcom,geni-uart";
				reg = <0 0x00a98000 0 0x4000>;
				clock-names = "se";
				clocks = <&gcc GCC_QUPV3_WRAP1_S6_CLK>;
				pinctrl-names = "default";
				pinctrl-0 = <&qup_uart14_cts>, <&qup_uart14_rts>, <&qup_uart14_tx>, <&qup_uart14_rx>;
				interrupts = <GIC_SPI 368 IRQ_TYPE_LEVEL_HIGH>;
				power-domains = <&rpmhpd SC7280_CX>;
				operating-points-v2 = <&qup_opp_table>;
				interconnects = <&clk_virt MASTER_QUP_CORE_1 0 &clk_virt SLAVE_QUP_CORE_1 0>,
						<&gem_noc MASTER_APPSS_PROC 0 &cnoc2 SLAVE_QUP_1 0>;
				interconnect-names = "qup-core", "qup-config";
				status = "disabled";
			};

			i2c15: i2c@a9c000 {
				compatible = "qcom,geni-i2c";
				reg = <0 0x00a9c000 0 0x4000>;
				clock-names = "se";
				clocks = <&gcc GCC_QUPV3_WRAP1_S7_CLK>;
				pinctrl-names = "default";
				pinctrl-0 = <&qup_i2c15_data_clk>;
				interrupts = <GIC_SPI 369 IRQ_TYPE_LEVEL_HIGH>;
				#address-cells = <1>;
				#size-cells = <0>;
				interconnects = <&clk_virt MASTER_QUP_CORE_1 0 &clk_virt SLAVE_QUP_CORE_1 0>,
						<&gem_noc MASTER_APPSS_PROC 0 &cnoc2 SLAVE_QUP_1 0>,
						<&aggre2_noc MASTER_QUP_1 0 &mc_virt SLAVE_EBI1 0>;
				interconnect-names = "qup-core", "qup-config",
							"qup-memory";
				status = "disabled";
			};

			spi15: spi@a9c000 {
				compatible = "qcom,geni-spi";
				reg = <0 0x00a9c000 0 0x4000>;
				clock-names = "se";
				clocks = <&gcc GCC_QUPV3_WRAP1_S7_CLK>;
				pinctrl-names = "default";
				pinctrl-0 = <&qup_spi15_data_clk>, <&qup_spi15_cs>, <&qup_spi15_cs_gpio>;
				interrupts = <GIC_SPI 369 IRQ_TYPE_LEVEL_HIGH>;
				#address-cells = <1>;
				#size-cells = <0>;
				power-domains = <&rpmhpd SC7280_CX>;
				operating-points-v2 = <&qup_opp_table>;
				interconnects = <&clk_virt MASTER_QUP_CORE_1 0 &clk_virt SLAVE_QUP_CORE_1 0>,
						<&gem_noc MASTER_APPSS_PROC 0 &cnoc2 SLAVE_QUP_1 0>;
				interconnect-names = "qup-core", "qup-config";
				status = "disabled";
			};

			uart15: serial@a9c000 {
				compatible = "qcom,geni-uart";
				reg = <0 0x00a9c000 0 0x4000>;
				clock-names = "se";
				clocks = <&gcc GCC_QUPV3_WRAP1_S7_CLK>;
				pinctrl-names = "default";
				pinctrl-0 = <&qup_uart15_cts>, <&qup_uart15_rts>, <&qup_uart15_tx>, <&qup_uart15_rx>;
				interrupts = <GIC_SPI 369 IRQ_TYPE_LEVEL_HIGH>;
				power-domains = <&rpmhpd SC7280_CX>;
				operating-points-v2 = <&qup_opp_table>;
				interconnects = <&clk_virt MASTER_QUP_CORE_1 0 &clk_virt SLAVE_QUP_CORE_1 0>,
						<&gem_noc MASTER_APPSS_PROC 0 &cnoc2 SLAVE_QUP_1 0>;
				interconnect-names = "qup-core", "qup-config";
				status = "disabled";
			};
		};

		stm@6002000 {
			compatible = "arm,coresight-stm", "arm,primecell";
			reg = <0 0x06002000 0 0x1000>,
			      <0 0x16280000 0 0x180000>;
			reg-names = "stm-base", "stm-stimulus-base";

			clocks = <&aoss_qmp>;
			clock-names = "apb_pclk";

			out-ports {
				port {
					stm_out: endpoint {
						remote-endpoint = <&funnel0_in7>;
					};
				};
			};
		};

		funnel@6041000 {
			compatible = "arm,coresight-dynamic-funnel", "arm,primecell";
			reg = <0 0x06041000 0 0x1000>;

			clocks = <&aoss_qmp>;
			clock-names = "apb_pclk";

			out-ports {
				port {
					funnel0_out: endpoint {
						remote-endpoint = <&merge_funnel_in0>;
					};
				};
			};

			in-ports {
				#address-cells = <1>;
				#size-cells = <0>;

				port@7 {
					reg = <7>;
					funnel0_in7: endpoint {
						remote-endpoint = <&stm_out>;
					};
				};
			};
		};

		funnel@6042000 {
			compatible = "arm,coresight-dynamic-funnel", "arm,primecell";
			reg = <0 0x06042000 0 0x1000>;

			clocks = <&aoss_qmp>;
			clock-names = "apb_pclk";

			out-ports {
				port {
					funnel1_out: endpoint {
						remote-endpoint = <&merge_funnel_in1>;
					};
				};
			};

			in-ports {
				#address-cells = <1>;
				#size-cells = <0>;

				port@4 {
					reg = <4>;
					funnel1_in4: endpoint {
						remote-endpoint = <&apss_merge_funnel_out>;
					};
				};
			};
		};

		funnel@6045000 {
			compatible = "arm,coresight-dynamic-funnel", "arm,primecell";
			reg = <0 0x06045000 0 0x1000>;

			clocks = <&aoss_qmp>;
			clock-names = "apb_pclk";

			out-ports {
				port {
					merge_funnel_out: endpoint {
						remote-endpoint = <&swao_funnel_in>;
					};
				};
			};

			in-ports {
				#address-cells = <1>;
				#size-cells = <0>;

				port@0 {
					reg = <0>;
					merge_funnel_in0: endpoint {
						remote-endpoint = <&funnel0_out>;
					};
				};

				port@1 {
					reg = <1>;
					merge_funnel_in1: endpoint {
						remote-endpoint = <&funnel1_out>;
					};
				};
			};
		};

		replicator@6046000 {
			compatible = "arm,coresight-dynamic-replicator", "arm,primecell";
			reg = <0 0x06046000 0 0x1000>;

			clocks = <&aoss_qmp>;
			clock-names = "apb_pclk";

			out-ports {
				port {
					replicator_out: endpoint {
						remote-endpoint = <&etr_in>;
					};
				};
			};

			in-ports {
				port {
					replicator_in: endpoint {
						remote-endpoint = <&swao_replicator_out>;
					};
				};
			};
		};

		etr@6048000 {
			compatible = "arm,coresight-tmc", "arm,primecell";
			reg = <0 0x06048000 0 0x1000>;
			iommus = <&apps_smmu 0x04c0 0>;

			clocks = <&aoss_qmp>;
			clock-names = "apb_pclk";
			arm,scatter-gather;

			in-ports {
				port {
					etr_in: endpoint {
						remote-endpoint = <&replicator_out>;
					};
				};
			};
		};

		funnel@6b04000 {
			compatible = "arm,coresight-dynamic-funnel", "arm,primecell";
			reg = <0 0x06b04000 0 0x1000>;

			clocks = <&aoss_qmp>;
			clock-names = "apb_pclk";

			out-ports {
				port {
					swao_funnel_out: endpoint {
						remote-endpoint = <&etf_in>;
					};
				};
			};

			in-ports {
				#address-cells = <1>;
				#size-cells = <0>;

				port@7 {
					reg = <7>;
					swao_funnel_in: endpoint {
						remote-endpoint = <&merge_funnel_out>;
					};
				};
			};
		};

		etf@6b05000 {
			compatible = "arm,coresight-tmc", "arm,primecell";
			reg = <0 0x06b05000 0 0x1000>;

			clocks = <&aoss_qmp>;
			clock-names = "apb_pclk";

			out-ports {
				port {
					etf_out: endpoint {
						remote-endpoint = <&swao_replicator_in>;
					};
				};
			};

			in-ports {
				port {
					etf_in: endpoint {
						remote-endpoint = <&swao_funnel_out>;
					};
				};
			};
		};

		replicator@6b06000 {
			compatible = "arm,coresight-dynamic-replicator", "arm,primecell";
			reg = <0 0x06b06000 0 0x1000>;

			clocks = <&aoss_qmp>;
			clock-names = "apb_pclk";
			qcom,replicator-loses-context;

			out-ports {
				port {
					swao_replicator_out: endpoint {
						remote-endpoint = <&replicator_in>;
					};
				};
			};

			in-ports {
				port {
					swao_replicator_in: endpoint {
						remote-endpoint = <&etf_out>;
					};
				};
			};
		};

		etm@7040000 {
			compatible = "arm,coresight-etm4x", "arm,primecell";
			reg = <0 0x07040000 0 0x1000>;

			cpu = <&CPU0>;

			clocks = <&aoss_qmp>;
			clock-names = "apb_pclk";
			arm,coresight-loses-context-with-cpu;
			qcom,skip-power-up;

			out-ports {
				port {
					etm0_out: endpoint {
						remote-endpoint = <&apss_funnel_in0>;
					};
				};
			};
		};

		etm@7140000 {
			compatible = "arm,coresight-etm4x", "arm,primecell";
			reg = <0 0x07140000 0 0x1000>;

			cpu = <&CPU1>;

			clocks = <&aoss_qmp>;
			clock-names = "apb_pclk";
			arm,coresight-loses-context-with-cpu;
			qcom,skip-power-up;

			out-ports {
				port {
					etm1_out: endpoint {
						remote-endpoint = <&apss_funnel_in1>;
					};
				};
			};
		};

		etm@7240000 {
			compatible = "arm,coresight-etm4x", "arm,primecell";
			reg = <0 0x07240000 0 0x1000>;

			cpu = <&CPU2>;

			clocks = <&aoss_qmp>;
			clock-names = "apb_pclk";
			arm,coresight-loses-context-with-cpu;
			qcom,skip-power-up;

			out-ports {
				port {
					etm2_out: endpoint {
						remote-endpoint = <&apss_funnel_in2>;
					};
				};
			};
		};

		etm@7340000 {
			compatible = "arm,coresight-etm4x", "arm,primecell";
			reg = <0 0x07340000 0 0x1000>;

			cpu = <&CPU3>;

			clocks = <&aoss_qmp>;
			clock-names = "apb_pclk";
			arm,coresight-loses-context-with-cpu;
			qcom,skip-power-up;

			out-ports {
				port {
					etm3_out: endpoint {
						remote-endpoint = <&apss_funnel_in3>;
					};
				};
			};
		};

		etm@7440000 {
			compatible = "arm,coresight-etm4x", "arm,primecell";
			reg = <0 0x07440000 0 0x1000>;

			cpu = <&CPU4>;

			clocks = <&aoss_qmp>;
			clock-names = "apb_pclk";
			arm,coresight-loses-context-with-cpu;
			qcom,skip-power-up;

			out-ports {
				port {
					etm4_out: endpoint {
						remote-endpoint = <&apss_funnel_in4>;
					};
				};
			};
		};

		etm@7540000 {
			compatible = "arm,coresight-etm4x", "arm,primecell";
			reg = <0 0x07540000 0 0x1000>;

			cpu = <&CPU5>;

			clocks = <&aoss_qmp>;
			clock-names = "apb_pclk";
			arm,coresight-loses-context-with-cpu;
			qcom,skip-power-up;

			out-ports {
				port {
					etm5_out: endpoint {
						remote-endpoint = <&apss_funnel_in5>;
					};
				};
			};
		};

		etm@7640000 {
			compatible = "arm,coresight-etm4x", "arm,primecell";
			reg = <0 0x07640000 0 0x1000>;

			cpu = <&CPU6>;

			clocks = <&aoss_qmp>;
			clock-names = "apb_pclk";
			arm,coresight-loses-context-with-cpu;
			qcom,skip-power-up;

			out-ports {
				port {
					etm6_out: endpoint {
						remote-endpoint = <&apss_funnel_in6>;
					};
				};
			};
		};

		etm@7740000 {
			compatible = "arm,coresight-etm4x", "arm,primecell";
			reg = <0 0x07740000 0 0x1000>;

			cpu = <&CPU7>;

			clocks = <&aoss_qmp>;
			clock-names = "apb_pclk";
			arm,coresight-loses-context-with-cpu;
			qcom,skip-power-up;

			out-ports {
				port {
					etm7_out: endpoint {
						remote-endpoint = <&apss_funnel_in7>;
					};
				};
			};
		};

		funnel@7800000 { /* APSS Funnel */
			compatible = "arm,coresight-dynamic-funnel", "arm,primecell";
			reg = <0 0x07800000 0 0x1000>;

			clocks = <&aoss_qmp>;
			clock-names = "apb_pclk";

			out-ports {
				port {
					apss_funnel_out: endpoint {
						remote-endpoint = <&apss_merge_funnel_in>;
					};
				};
			};

			in-ports {
				#address-cells = <1>;
				#size-cells = <0>;

				port@0 {
					reg = <0>;
					apss_funnel_in0: endpoint {
						remote-endpoint = <&etm0_out>;
					};
				};

				port@1 {
					reg = <1>;
					apss_funnel_in1: endpoint {
						remote-endpoint = <&etm1_out>;
					};
				};

				port@2 {
					reg = <2>;
					apss_funnel_in2: endpoint {
						remote-endpoint = <&etm2_out>;
					};
				};

				port@3 {
					reg = <3>;
					apss_funnel_in3: endpoint {
						remote-endpoint = <&etm3_out>;
					};
				};

				port@4 {
					reg = <4>;
					apss_funnel_in4: endpoint {
						remote-endpoint = <&etm4_out>;
					};
				};

				port@5 {
					reg = <5>;
					apss_funnel_in5: endpoint {
						remote-endpoint = <&etm5_out>;
					};
				};

				port@6 {
					reg = <6>;
					apss_funnel_in6: endpoint {
						remote-endpoint = <&etm6_out>;
					};
				};

				port@7 {
					reg = <7>;
					apss_funnel_in7: endpoint {
						remote-endpoint = <&etm7_out>;
					};
				};
			};
		};

		funnel@7810000 {
			compatible = "arm,coresight-dynamic-funnel", "arm,primecell";
			reg = <0 0x07810000 0 0x1000>;

			clocks = <&aoss_qmp>;
			clock-names = "apb_pclk";

			out-ports {
				port {
					apss_merge_funnel_out: endpoint {
						remote-endpoint = <&funnel1_in4>;
					};
				};
			};

			in-ports {
				port {
					apss_merge_funnel_in: endpoint {
						remote-endpoint = <&apss_funnel_out>;
					};
				};
			};
		};

		system-cache-controller@9200000 {
			compatible = "qcom,sc7280-llcc";
			reg = <0 0x09200000 0 0xd0000>, <0 0x09600000 0 0x50000>;
			reg-names = "llcc_base", "llcc_broadcast_base";
			interrupts = <GIC_SPI 582 IRQ_TYPE_LEVEL_HIGH>;
		};

		pdc: interrupt-controller@b220000 {
			compatible = "qcom,sc7280-pdc", "qcom,pdc";
			reg = <0 0x0b220000 0 0x30000>;
			qcom,pdc-ranges = <0 480 40>, <40 140 14>, <54 263 1>,
					  <55 306 4>, <59 312 3>, <62 374 2>,
					  <64 434 2>, <66 438 3>, <69 86 1>,
					  <70 520 54>, <124 609 31>, <155 63 1>,
					  <156 716 12>;
			#interrupt-cells = <2>;
			interrupt-parent = <&intc>;
			interrupt-controller;
		};

		aoss_qmp: power-controller@c300000 {
			compatible = "qcom,sc7280-aoss-qmp";
			reg = <0 0x0c300000 0 0x100000>;
			interrupts-extended = <&ipcc IPCC_CLIENT_AOP
						     IPCC_MPROC_SIGNAL_GLINK_QMP
						     IRQ_TYPE_EDGE_RISING>;
			mboxes = <&ipcc IPCC_CLIENT_AOP
					IPCC_MPROC_SIGNAL_GLINK_QMP>;

			#clock-cells = <0>;
			#power-domain-cells = <1>;
		};

		spmi_bus: spmi@c440000 {
			compatible = "qcom,spmi-pmic-arb";
			reg = <0 0x0c440000 0 0x1100>,
			      <0 0x0c600000 0 0x2000000>,
			      <0 0x0e600000 0 0x100000>,
			      <0 0x0e700000 0 0xa0000>,
			      <0 0x0c40a000 0 0x26000>;
			reg-names = "core", "chnls", "obsrvr", "intr", "cnfg";
			interrupt-names = "periph_irq";
			interrupts-extended = <&pdc 1 IRQ_TYPE_LEVEL_HIGH>;
			qcom,ee = <0>;
			qcom,channel = <0>;
			#address-cells = <1>;
			#size-cells = <1>;
			interrupt-controller;
			#interrupt-cells = <4>;
		};

		tlmm: pinctrl@f100000 {
			compatible = "qcom,sc7280-pinctrl";
			reg = <0 0x0f100000 0 0x300000>;
			interrupts = <GIC_SPI 208 IRQ_TYPE_LEVEL_HIGH>;
			gpio-controller;
			#gpio-cells = <2>;
			interrupt-controller;
			#interrupt-cells = <2>;
			gpio-ranges = <&tlmm 0 0 175>;
			wakeup-parent = <&pdc>;

			qspi_clk: qspi-clk {
				pins = "gpio14";
				function = "qspi_clk";
			};

			qspi_cs0: qspi-cs0 {
				pins = "gpio15";
				function = "qspi_cs";
			};

			qspi_cs1: qspi-cs1 {
				pins = "gpio19";
				function = "qspi_cs";
			};

			qspi_data01: qspi-data01 {
				pins = "gpio12", "gpio13";
				function = "qspi_data";
			};

			qspi_data12: qspi-data12 {
				pins = "gpio16", "gpio17";
				function = "qspi_data";
			};

			qup_i2c0_data_clk:qup-i2c0-data-clk {
				pins = "gpio0", "gpio1";
				function = "qup00";
			};

			qup_i2c1_data_clk:qup-i2c1-data-clk {
				pins = "gpio4", "gpio5";
				function = "qup01";
			};

			qup_i2c2_data_clk:qup-i2c2-data-clk {
				pins = "gpio8", "gpio9";
				function = "qup02";
			};

			qup_i2c3_data_clk:qup-i2c3-data-clk {
				pins = "gpio12", "gpio13";
				function = "qup03";
			};

			qup_i2c4_data_clk:qup-i2c4-data-clk {
				pins = "gpio16", "gpio17";
				function = "qup04";
			};

			qup_i2c5_data_clk:qup-i2c5-data-clk {
				pins = "gpio20", "gpio21";
				function = "qup05";
			};

			qup_i2c6_data_clk:qup-i2c6-data-clk {
				pins = "gpio24", "gpio25";
				function = "qup06";
			};

			qup_i2c7_data_clk:qup-i2c7-data-clk {
				pins = "gpio28", "gpio29";
				function = "qup07";
			};

			qup_i2c8_data_clk:qup-i2c8-data-clk {
				pins = "gpio32", "gpio33";
				function = "qup08";
			};

			qup_i2c9_data_clk:qup-i2c9-data-clk {
				pins = "gpio36", "gpio37";
				function = "qup09";
			};

			qup_i2c10_data_clk:qup-i2c10-data-clk {
				pins = "gpio40", "gpio41";
				function = "qup10";
			};

			qup_i2c11_data_clk:qup-i2c11-data-clk {
				pins = "gpio44", "gpio45";
				function = "qup11";
			};

			qup_i2c12_data_clk:qup-i2c12-data-clk {
				pins = "gpio48", "gpio49";
				function = "qup12";
			};

			qup_i2c13_data_clk:qup-i2c13-data-clk {
				pins = "gpio52", "gpio53";
				function = "qup13";
			};

			qup_i2c14_data_clk:qup-i2c14-data-clk {
				pins = "gpio56", "gpio57";
				function = "qup14";
			};

			qup_i2c15_data_clk:qup-i2c15-data-clk {
				pins = "gpio60", "gpio61";
				function = "qup15";
			};

			qup_spi0_data_clk: qup-spi0-data-clk {
				pins = "gpio0", "gpio1", "gpio2";
				function = "qup00";
			};

			qup_spi0_cs: qup-spi0-cs {
				pins = "gpio3";
				function = "qup00";
			};

			qup_spi0_cs_gpio: qup-spi0-cs_gpio {
				pins = "gpio3";
				function = "gpio";
			};

			qup_spi1_data_clk: qup-spi1-data-clk {
				pins = "gpio4", "gpio5", "gpio6";
				function = "qup01";
			};

			qup_spi1_cs: qup-spi1-cs {
				pins = "gpio7";
				function = "qup01";
			};

			qup_spi1_cs_gpio: qup-spi1-cs_gpio {
				pins = "gpio7";
				function = "gpio";
			};

			qup_spi2_data_clk: qup-spi2-data-clk {
				pins = "gpio8", "gpio9", "gpio10";
				function = "qup02";
			};

			qup_spi2_cs: qup-spi2-cs {
				pins = "gpio11";
				function = "qup02";
			};

			qup_spi2_cs_gpio: qup-spi2-cs_gpio {
				pins = "gpio11";
				function = "gpio";
			};

			qup_spi3_data_clk: qup-spi3-data-clk {
				pins = "gpio12", "gpio13", "gpio14";
				function = "qup03";
			};

			qup_spi3_cs: qup-spi3-cs {
				pins = "gpio15";
				function = "qup03";
			};

			qup_spi3_cs_gpio: qup-spi3-cs_gpio {
				pins = "gpio15";
				function = "gpio";
			};

			qup_spi4_data_clk: qup-spi4-data-clk {
				pins = "gpio16", "gpio17", "gpio18";
				function = "qup04";
			};

			qup_spi4_cs: qup-spi4-cs {
				pins = "gpio19";
				function = "qup04";
			};

			qup_spi4_cs_gpio: qup-spi4-cs_gpio {
				pins = "gpio19";
				function = "gpio";
			};

			qup_spi5_data_clk: qup-spi5-data-clk {
				pins = "gpio20", "gpio21", "gpio22";
				function = "qup05";
			};

			qup_spi5_cs: qup-spi5-cs {
				pins = "gpio23";
				function = "qup05";
			};

			qup_spi5_cs_gpio: qup-spi5-cs_gpio {
				pins = "gpio23";
				function = "gpio";
			};

			qup_spi6_data_clk: qup-spi6-data-clk {
				pins = "gpio24", "gpio25", "gpio26";
				function = "qup06";
			};

			qup_spi6_cs: qup-spi6-cs {
				pins = "gpio27";
				function = "qup06";
			};

			qup_spi6_cs_gpio: qup-spi6-cs_gpio {
				pins = "gpio27";
				function = "gpio";
			};

			qup_spi7_data_clk: qup-spi7-data-clk {
				pins = "gpio28", "gpio29", "gpio30";
				function = "qup07";
			};

			qup_spi7_cs: qup-spi7-cs {
				pins = "gpio31";
				function = "qup07";
			};

			qup_spi7_cs_gpio: qup-spi7-cs_gpio {
				pins = "gpio31";
				function = "gpio";
			};

			qup_spi8_data_clk: qup-spi8-data-clk {
				pins = "gpio32", "gpio33", "gpio34";
				function = "qup08";
			};

			qup_spi8_cs: qup-spi8-cs {
				pins = "gpio35";
				function = "qup08";
			};

			qup_spi8_cs_gpio: qup-spi8-cs_gpio {
				pins = "gpio35";
				function = "gpio";
			};

			qup_spi9_data_clk: qup-spi9-data-clk {
				pins = "gpio36", "gpio37", "gpio38";
				function = "qup09";
			};

			qup_spi9_cs: qup-spi9-cs {
				pins = "gpio39";
				function = "qup09";
			};

			qup_spi9_cs_gpio: qup-spi9-cs_gpio {
				pins = "gpio39";
				function = "gpio";
			};

			qup_spi10_data_clk: qup-spi10-data-clk {
				pins = "gpio40", "gpio41", "gpio42";
				function = "qup10";
			};

			qup_spi10_cs: qup-spi10-cs {
				pins = "gpio43";
				function = "qup10";
			};

			qup_spi10_cs_gpio: qup-spi10-cs_gpio {
				pins = "gpio43";
				function = "gpio";
			};

			qup_spi11_data_clk: qup-spi11-data-clk {
				pins = "gpio44", "gpio45", "gpio46";
				function = "qup11";
			};

			qup_spi11_cs: qup-spi11-cs {
				pins = "gpio47";
				function = "qup11";
			};

			qup_spi11_cs_gpio: qup-spi11-cs_gpio {
				pins = "gpio47";
				function = "gpio";
			};

			qup_spi12_data_clk: qup-spi12-data-clk {
				pins = "gpio48", "gpio49", "gpio50";
				function = "qup12";
			};

			qup_spi12_cs: qup-spi12-cs {
				pins = "gpio51";
				function = "qup12";
			};

			qup_spi12_cs_gpio: qup-spi12-cs_gpio {
				pins = "gpio51";
				function = "gpio";
			};

			qup_spi13_data_clk: qup-spi13-data-clk {
				pins = "gpio52", "gpio53", "gpio54";
				function = "qup13";
			};

			qup_spi13_cs: qup-spi13-cs {
				pins = "gpio55";
				function = "qup13";
			};

			qup_spi13_cs_gpio: qup-spi13-cs_gpio {
				pins = "gpio55";
				function = "gpio";
			};

			qup_spi14_data_clk: qup-spi14-data-clk {
				pins = "gpio56", "gpio57", "gpio58";
				function = "qup14";
			};

			qup_spi14_cs: qup-spi14-cs {
				pins = "gpio59";
				function = "qup14";
			};

			qup_spi14_cs_gpio: qup-spi14-cs_gpio {
				pins = "gpio59";
				function = "gpio";
			};

			qup_spi15_data_clk: qup-spi15-data-clk {
				pins = "gpio60", "gpio61", "gpio62";
				function = "qup15";
			};

			qup_spi15_cs: qup-spi15-cs {
				pins = "gpio63";
				function = "qup15";
			};

			qup_spi15_cs_gpio: qup-spi15-cs_gpio {
				pins = "gpio63";
				function = "gpio";
			};

			qup_uart0_cts: qup-uart0-cts {
				pins = "gpio0";
				function = "qup00";
			};

			qup_uart0_rts: qup-uart0-rts {
				pins = "gpio1";
				function = "qup00";
			};

			qup_uart0_tx: qup-uart0-tx {
				pins = "gpio2";
				function = "qup00";
			};

			qup_uart0_rx: qup-uart0-rx {
				pins = "gpio3";
				function = "qup00";
			};

			qup_uart1_cts: qup-uart1-cts {
				pins = "gpio4";
				function = "qup01";
			};

			qup_uart1_rts: qup-uart1-rts {
				pins = "gpio5";
				function = "qup01";
			};

			qup_uart1_tx: qup-uart1-tx {
				pins = "gpio6";
				function = "qup01";
			};

			qup_uart1_rx: qup-uart1-rx {
				pins = "gpio7";
				function = "qup01";
			};

			qup_uart2_cts: qup-uart2-cts {
				pins = "gpio8";
				function = "qup02";
			};

			qup_uart2_rts: qup-uart2-rts {
				pins = "gpio9";
				function = "qup02";
			};

			qup_uart2_tx: qup-uart2-tx {
				pins = "gpio10";
				function = "qup02";
			};

			qup_uart2_rx: qup-uart2-rx {
				pins = "gpio11";
				function = "qup02";
			};

			qup_uart3_cts: qup-uart3-cts {
				pins = "gpio12";
				function = "qup03";
			};

			qup_uart3_rts: qup-uart3-rts {
				pins = "gpio13";
				function = "qup03";
			};

			qup_uart3_tx: qup-uart3-tx {
				pins = "gpio14";
				function = "qup03";
			};

			qup_uart3_rx: qup-uart3-rx {
				pins = "gpio15";
				function = "qup03";
			};

			qup_uart4_cts: qup-uart4-cts {
				pins = "gpio16";
				function = "qup04";
			};

			qup_uart4_rts: qup-uart4-rts {
				pins = "gpio17";
				function = "qup04";
			};

			qup_uart4_tx: qup-uart4-tx {
				pins = "gpio18";
				function = "qup04";
			};

			qup_uart4_rx: qup-uart4-rx {
				pins = "gpio19";
				function = "qup04";
			};

			qup_uart5_cts: qup-uart5-cts {
				pins = "gpio20";
				function = "qup05";
			};

			qup_uart5_rts: qup-uart5-rts {
				pins = "gpio21";
				function = "qup05";
			};

			qup_uart5_tx: qup-uart5-tx {
				pins = "gpio22";
				function = "qup05";
			};

			qup_uart5_rx: qup-uart5-rx {
				pins = "gpio23";
				function = "qup05";
			};

			qup_uart6_cts: qup-uart6-cts {
				pins = "gpio24";
				function = "qup06";
			};

			qup_uart6_rts: qup-uart6-rts {
				pins = "gpio25";
				function = "qup06";
			};

			qup_uart6_tx: qup-uart6-tx {
				pins = "gpio26";
				function = "qup06";
			};

			qup_uart6_rx: qup-uart6-rx {
				pins = "gpio27";
				function = "qup06";
			};

			qup_uart7_cts: qup-uart7-cts {
				pins = "gpio28";
				function = "qup07";
			};

			qup_uart7_rts: qup-uart7-rts {
				pins = "gpio29";
				function = "qup07";
			};

			qup_uart7_tx: qup-uart7-tx {
				pins = "gpio30";
				function = "qup07";
			};

			qup_uart7_rx: qup-uart7-rx {
				pins = "gpio31";
				function = "qup07";
			};

			qup_uart8_cts: qup-uart8-cts {
				pins = "gpio32";
				function = "qup08";
			};

			qup_uart8_rts: qup-uart8-rts {
				pins = "gpio33";
				function = "qup08";
			};

			qup_uart8_tx: qup-uart8-tx {
				pins = "gpio34";
				function = "qup08";
			};

			qup_uart8_rx: qup-uart8-rx {
				pins = "gpio35";
				function = "qup08";
			};

			qup_uart9_cts: qup-uart9-cts {
				pins = "gpio36";
				function = "qup09";
			};

			qup_uart9_rts: qup-uart9-rts {
				pins = "gpio37";
				function = "qup09";
			};

			qup_uart9_tx: qup-uart9-tx {
				pins = "gpio38";
				function = "qup09";
			};

			qup_uart9_rx: qup-uart9-rx {
				pins = "gpio39";
				function = "qup09";
			};

			qup_uart10_cts: qup-uart10-cts {
				pins = "gpio40";
				function = "qup10";
			};

			qup_uart10_rts: qup-uart10-rts {
				pins = "gpio41";
				function = "qup10";
			};

			qup_uart10_tx: qup-uart10-tx {
				pins = "gpio42";
				function = "qup10";
			};

			qup_uart10_rx: qup-uart10-rx {
				pins = "gpio43";
				function = "qup10";
			};

			qup_uart11_cts: qup-uart11-cts {
				pins = "gpio44";
				function = "qup11";
			};

			qup_uart11_rts: qup-uart11-rts {
				pins = "gpio45";
				function = "qup11";
			};

			qup_uart11_tx: qup-uart11-tx {
				pins = "gpio46";
				function = "qup11";
			};

			qup_uart11_rx: qup-uart11-rx {
				pins = "gpio47";
				function = "qup11";
			};

			qup_uart12_cts: qup-uart12-cts {
				pins = "gpio48";
				function = "qup12";
			};

			qup_uart12_rts: qup-uart12-rts {
				pins = "gpio49";
				function = "qup12";
			};

			qup_uart12_tx: qup-uart12-tx {
				pins = "gpio50";
				function = "qup12";
			};

			qup_uart12_rx: qup-uart12-rx {
				pins = "gpio51";
				function = "qup12";
			};

			qup_uart13_cts: qup-uart13-cts {
				pins = "gpio52";
				function = "qup13";
			};

			qup_uart13_rts: qup-uart13-rts {
				pins = "gpio53";
				function = "qup13";
			};

			qup_uart13_tx: qup-uart13-tx {
				pins = "gpio54";
				function = "qup13";
			};

			qup_uart13_rx: qup-uart13-rx {
				pins = "gpio55";
				function = "qup13";
			};

			qup_uart14_cts: qup-uart14-cts {
				pins = "gpio56";
				function = "qup14";
			};

			qup_uart14_rts: qup-uart14-rts {
				pins = "gpio57";
				function = "qup14";
			};

			qup_uart14_tx: qup-uart14-tx {
				pins = "gpio58";
				function = "qup14";
			};

			qup_uart14_rx: qup-uart14-rx {
				pins = "gpio59";
				function = "qup14";
			};

			qup_uart15_cts: qup-uart15-cts {
				pins = "gpio60";
				function = "qup15";
			};

			qup_uart15_rts: qup-uart15-rts {
				pins = "gpio61";
				function = "qup15";
			};

			qup_uart15_tx: qup-uart15-tx {
				pins = "gpio62";
				function = "qup15";
			};

			qup_uart15_rx: qup-uart15-rx {
				pins = "gpio63";
				function = "qup15";
			};

		};

		qspi_opp_table: qspi-opp-table {
			compatible = "operating-points-v2";

			opp-75000000 {
				opp-hz = /bits/ 64 <75000000>;
				required-opps = <&rpmhpd_opp_low_svs>;
			};

			opp-150000000 {
				opp-hz = /bits/ 64 <150000000>;
				required-opps = <&rpmhpd_opp_svs>;
			};

			opp-300000000 {
				opp-hz = /bits/ 64 <300000000>;
				required-opps = <&rpmhpd_opp_nom>;
			};
		};

		qspi: spi@88dc000 {
			compatible = "qcom,qspi-v1";
			reg = <0 0x088dc000 0 0x1000>;
			#address-cells = <1>;
			#size-cells = <0>;
			interrupts = <GIC_SPI 82 IRQ_TYPE_LEVEL_HIGH>;
			clocks = <&gcc GCC_QSPI_CNOC_PERIPH_AHB_CLK>,
				 <&gcc GCC_QSPI_CORE_CLK>;
			clock-names = "iface", "core";
			interconnects = <&gem_noc MASTER_APPSS_PROC 0
					&cnoc2 SLAVE_QSPI_0 0>;
			interconnect-names = "qspi-config";
			power-domains = <&rpmhpd SC7280_CX>;
			operating-points-v2 = <&qspi_opp_table>;
			status = "disabled";
		};

		apps_smmu: iommu@15000000 {
			compatible = "qcom,sc7280-smmu-500", "arm,mmu-500";
			reg = <0 0x15000000 0 0x100000>;
			#iommu-cells = <2>;
			#global-interrupts = <1>;
			dma-coherent;
			interrupts = <GIC_SPI 65 IRQ_TYPE_LEVEL_HIGH>,
				     <GIC_SPI 96 IRQ_TYPE_LEVEL_HIGH>,
				     <GIC_SPI 97 IRQ_TYPE_LEVEL_HIGH>,
				     <GIC_SPI 98 IRQ_TYPE_LEVEL_HIGH>,
				     <GIC_SPI 99 IRQ_TYPE_LEVEL_HIGH>,
				     <GIC_SPI 100 IRQ_TYPE_LEVEL_HIGH>,
				     <GIC_SPI 101 IRQ_TYPE_LEVEL_HIGH>,
				     <GIC_SPI 102 IRQ_TYPE_LEVEL_HIGH>,
				     <GIC_SPI 103 IRQ_TYPE_LEVEL_HIGH>,
				     <GIC_SPI 104 IRQ_TYPE_LEVEL_HIGH>,
				     <GIC_SPI 105 IRQ_TYPE_LEVEL_HIGH>,
				     <GIC_SPI 106 IRQ_TYPE_LEVEL_HIGH>,
				     <GIC_SPI 107 IRQ_TYPE_LEVEL_HIGH>,
				     <GIC_SPI 108 IRQ_TYPE_LEVEL_HIGH>,
				     <GIC_SPI 109 IRQ_TYPE_LEVEL_HIGH>,
				     <GIC_SPI 110 IRQ_TYPE_LEVEL_HIGH>,
				     <GIC_SPI 111 IRQ_TYPE_LEVEL_HIGH>,
				     <GIC_SPI 112 IRQ_TYPE_LEVEL_HIGH>,
				     <GIC_SPI 113 IRQ_TYPE_LEVEL_HIGH>,
				     <GIC_SPI 114 IRQ_TYPE_LEVEL_HIGH>,
				     <GIC_SPI 115 IRQ_TYPE_LEVEL_HIGH>,
				     <GIC_SPI 116 IRQ_TYPE_LEVEL_HIGH>,
				     <GIC_SPI 117 IRQ_TYPE_LEVEL_HIGH>,
				     <GIC_SPI 118 IRQ_TYPE_LEVEL_HIGH>,
				     <GIC_SPI 181 IRQ_TYPE_LEVEL_HIGH>,
				     <GIC_SPI 182 IRQ_TYPE_LEVEL_HIGH>,
				     <GIC_SPI 183 IRQ_TYPE_LEVEL_HIGH>,
				     <GIC_SPI 184 IRQ_TYPE_LEVEL_HIGH>,
				     <GIC_SPI 185 IRQ_TYPE_LEVEL_HIGH>,
				     <GIC_SPI 186 IRQ_TYPE_LEVEL_HIGH>,
				     <GIC_SPI 187 IRQ_TYPE_LEVEL_HIGH>,
				     <GIC_SPI 188 IRQ_TYPE_LEVEL_HIGH>,
				     <GIC_SPI 189 IRQ_TYPE_LEVEL_HIGH>,
				     <GIC_SPI 190 IRQ_TYPE_LEVEL_HIGH>,
				     <GIC_SPI 191 IRQ_TYPE_LEVEL_HIGH>,
				     <GIC_SPI 192 IRQ_TYPE_LEVEL_HIGH>,
				     <GIC_SPI 315 IRQ_TYPE_LEVEL_HIGH>,
				     <GIC_SPI 316 IRQ_TYPE_LEVEL_HIGH>,
				     <GIC_SPI 317 IRQ_TYPE_LEVEL_HIGH>,
				     <GIC_SPI 318 IRQ_TYPE_LEVEL_HIGH>,
				     <GIC_SPI 319 IRQ_TYPE_LEVEL_HIGH>,
				     <GIC_SPI 320 IRQ_TYPE_LEVEL_HIGH>,
				     <GIC_SPI 321 IRQ_TYPE_LEVEL_HIGH>,
				     <GIC_SPI 322 IRQ_TYPE_LEVEL_HIGH>,
				     <GIC_SPI 323 IRQ_TYPE_LEVEL_HIGH>,
				     <GIC_SPI 324 IRQ_TYPE_LEVEL_HIGH>,
				     <GIC_SPI 325 IRQ_TYPE_LEVEL_HIGH>,
				     <GIC_SPI 326 IRQ_TYPE_LEVEL_HIGH>,
				     <GIC_SPI 327 IRQ_TYPE_LEVEL_HIGH>,
				     <GIC_SPI 328 IRQ_TYPE_LEVEL_HIGH>,
				     <GIC_SPI 329 IRQ_TYPE_LEVEL_HIGH>,
				     <GIC_SPI 330 IRQ_TYPE_LEVEL_HIGH>,
				     <GIC_SPI 331 IRQ_TYPE_LEVEL_HIGH>,
				     <GIC_SPI 332 IRQ_TYPE_LEVEL_HIGH>,
				     <GIC_SPI 333 IRQ_TYPE_LEVEL_HIGH>,
				     <GIC_SPI 334 IRQ_TYPE_LEVEL_HIGH>,
				     <GIC_SPI 335 IRQ_TYPE_LEVEL_HIGH>,
				     <GIC_SPI 336 IRQ_TYPE_LEVEL_HIGH>,
				     <GIC_SPI 337 IRQ_TYPE_LEVEL_HIGH>,
				     <GIC_SPI 338 IRQ_TYPE_LEVEL_HIGH>,
				     <GIC_SPI 339 IRQ_TYPE_LEVEL_HIGH>,
				     <GIC_SPI 340 IRQ_TYPE_LEVEL_HIGH>,
				     <GIC_SPI 341 IRQ_TYPE_LEVEL_HIGH>,
				     <GIC_SPI 342 IRQ_TYPE_LEVEL_HIGH>,
				     <GIC_SPI 343 IRQ_TYPE_LEVEL_HIGH>,
				     <GIC_SPI 344 IRQ_TYPE_LEVEL_HIGH>,
				     <GIC_SPI 345 IRQ_TYPE_LEVEL_HIGH>,
				     <GIC_SPI 395 IRQ_TYPE_LEVEL_HIGH>,
				     <GIC_SPI 396 IRQ_TYPE_LEVEL_HIGH>,
				     <GIC_SPI 397 IRQ_TYPE_LEVEL_HIGH>,
				     <GIC_SPI 398 IRQ_TYPE_LEVEL_HIGH>,
				     <GIC_SPI 399 IRQ_TYPE_LEVEL_HIGH>,
				     <GIC_SPI 400 IRQ_TYPE_LEVEL_HIGH>,
				     <GIC_SPI 401 IRQ_TYPE_LEVEL_HIGH>,
				     <GIC_SPI 402 IRQ_TYPE_LEVEL_HIGH>,
				     <GIC_SPI 403 IRQ_TYPE_LEVEL_HIGH>,
				     <GIC_SPI 404 IRQ_TYPE_LEVEL_HIGH>,
				     <GIC_SPI 405 IRQ_TYPE_LEVEL_HIGH>,
				     <GIC_SPI 406 IRQ_TYPE_LEVEL_HIGH>,
				     <GIC_SPI 407 IRQ_TYPE_LEVEL_HIGH>,
				     <GIC_SPI 408 IRQ_TYPE_LEVEL_HIGH>;
		};

		intc: interrupt-controller@17a00000 {
			compatible = "arm,gic-v3";
			#address-cells = <2>;
			#size-cells = <2>;
			ranges;
			#interrupt-cells = <3>;
			interrupt-controller;
			reg = <0 0x17a00000 0 0x10000>,     /* GICD */
			      <0 0x17a60000 0 0x100000>;    /* GICR * 8 */
			interrupts = <GIC_PPI 9 IRQ_TYPE_LEVEL_LOW>;

			gic-its@17a40000 {
				compatible = "arm,gic-v3-its";
				msi-controller;
				#msi-cells = <1>;
				reg = <0 0x17a40000 0 0x20000>;
				status = "disabled";
			};
		};

		watchdog@17c10000 {
			compatible = "qcom,apss-wdt-sc7280", "qcom,kpss-wdt";
			reg = <0 0x17c10000 0 0x1000>;
			clocks = <&sleep_clk>;
			interrupts = <GIC_SPI 0 IRQ_TYPE_LEVEL_HIGH>;
		};

		timer@17c20000 {
			#address-cells = <2>;
			#size-cells = <2>;
			ranges;
			compatible = "arm,armv7-timer-mem";
			reg = <0 0x17c20000 0 0x1000>;

			frame@17c21000 {
				frame-number = <0>;
				interrupts = <GIC_SPI 8 IRQ_TYPE_LEVEL_HIGH>,
					     <GIC_SPI 6 IRQ_TYPE_LEVEL_HIGH>;
				reg = <0 0x17c21000 0 0x1000>,
				      <0 0x17c22000 0 0x1000>;
			};

			frame@17c23000 {
				frame-number = <1>;
				interrupts = <GIC_SPI 9 IRQ_TYPE_LEVEL_HIGH>;
				reg = <0 0x17c23000 0 0x1000>;
				status = "disabled";
			};

			frame@17c25000 {
				frame-number = <2>;
				interrupts = <GIC_SPI 10 IRQ_TYPE_LEVEL_HIGH>;
				reg = <0 0x17c25000 0 0x1000>;
				status = "disabled";
			};

			frame@17c27000 {
				frame-number = <3>;
				interrupts = <GIC_SPI 11 IRQ_TYPE_LEVEL_HIGH>;
				reg = <0 0x17c27000 0 0x1000>;
				status = "disabled";
			};

			frame@17c29000 {
				frame-number = <4>;
				interrupts = <GIC_SPI 12 IRQ_TYPE_LEVEL_HIGH>;
				reg = <0 0x17c29000 0 0x1000>;
				status = "disabled";
			};

			frame@17c2b000 {
				frame-number = <5>;
				interrupts = <GIC_SPI 13 IRQ_TYPE_LEVEL_HIGH>;
				reg = <0 0x17c2b000 0 0x1000>;
				status = "disabled";
			};

			frame@17c2d000 {
				frame-number = <6>;
				interrupts = <GIC_SPI 14 IRQ_TYPE_LEVEL_HIGH>;
				reg = <0 0x17c2d000 0 0x1000>;
				status = "disabled";
			};
		};

		apps_rsc: rsc@18200000 {
			compatible = "qcom,rpmh-rsc";
			reg = <0 0x18200000 0 0x10000>,
			      <0 0x18210000 0 0x10000>,
			      <0 0x18220000 0 0x10000>;
			reg-names = "drv-0", "drv-1", "drv-2";
			interrupts = <GIC_SPI 3 IRQ_TYPE_LEVEL_HIGH>,
				     <GIC_SPI 4 IRQ_TYPE_LEVEL_HIGH>,
				     <GIC_SPI 5 IRQ_TYPE_LEVEL_HIGH>;
			qcom,tcs-offset = <0xd00>;
			qcom,drv-id = <2>;
			qcom,tcs-config = <ACTIVE_TCS  2>,
					  <SLEEP_TCS   3>,
					  <WAKE_TCS    3>,
					  <CONTROL_TCS 1>;

			rpmhpd: power-controller {
				compatible = "qcom,sc7280-rpmhpd";
				#power-domain-cells = <1>;
				operating-points-v2 = <&rpmhpd_opp_table>;

				rpmhpd_opp_table: opp-table {
					compatible = "operating-points-v2";

					rpmhpd_opp_ret: opp1 {
						opp-level = <RPMH_REGULATOR_LEVEL_RETENTION>;
					};

					rpmhpd_opp_low_svs: opp2 {
						opp-level = <RPMH_REGULATOR_LEVEL_LOW_SVS>;
					};

					rpmhpd_opp_svs: opp3 {
						opp-level = <RPMH_REGULATOR_LEVEL_SVS>;
					};

					rpmhpd_opp_svs_l1: opp4 {
						opp-level = <RPMH_REGULATOR_LEVEL_SVS_L1>;
					};

					rpmhpd_opp_svs_l2: opp5 {
						opp-level = <RPMH_REGULATOR_LEVEL_SVS_L2>;
					};

					rpmhpd_opp_nom: opp6 {
						opp-level = <RPMH_REGULATOR_LEVEL_NOM>;
					};

					rpmhpd_opp_nom_l1: opp7 {
						opp-level = <RPMH_REGULATOR_LEVEL_NOM_L1>;
					};

					rpmhpd_opp_turbo: opp8 {
						opp-level = <RPMH_REGULATOR_LEVEL_TURBO>;
					};

					rpmhpd_opp_turbo_l1: opp9 {
						opp-level = <RPMH_REGULATOR_LEVEL_TURBO_L1>;
					};
				};
			};

			rpmhcc: clock-controller {
				compatible = "qcom,sc7280-rpmh-clk";
				clocks = <&xo_board>;
				clock-names = "xo";
				#clock-cells = <1>;
			};
		};
	};

	timer {
		compatible = "arm,armv8-timer";
		interrupts = <GIC_PPI 13 IRQ_TYPE_LEVEL_LOW>,
			     <GIC_PPI 14 IRQ_TYPE_LEVEL_LOW>,
			     <GIC_PPI 11 IRQ_TYPE_LEVEL_LOW>,
			     <GIC_PPI 10 IRQ_TYPE_LEVEL_LOW>;
	};
};
